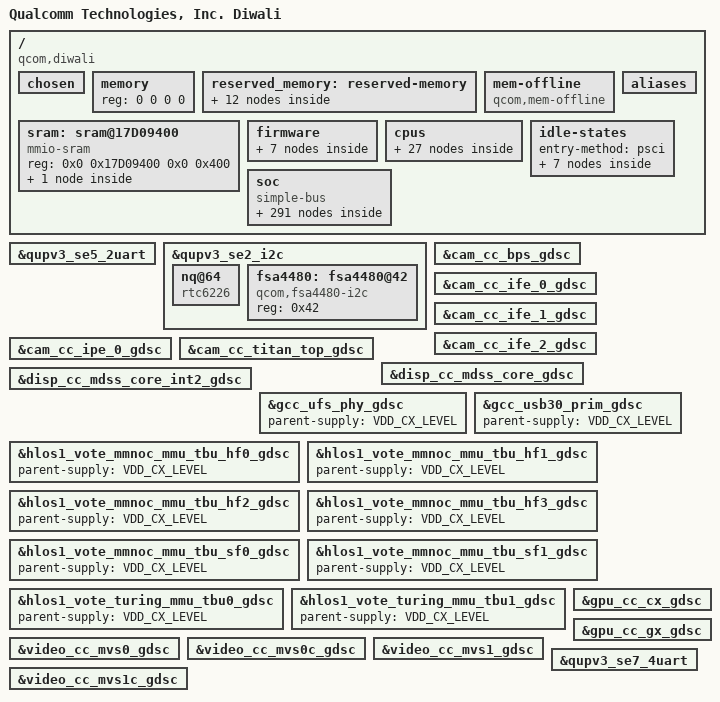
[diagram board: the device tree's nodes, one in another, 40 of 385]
#include <dt-bindings/clock/qcom,aop-qmp.h>
#include <dt-bindings/clock/qcom,camcc-diwali.h>
#include <dt-bindings/clock/qcom,dispcc-diwali.h>
#include <dt-bindings/clock/qcom,gcc-diwali.h>
#include <dt-bindings/clock/qcom,gpucc-diwali.h>
#include <dt-bindings/clock/qcom,rpmh.h>
#include <dt-bindings/clock/qcom,videocc-diwali.h>
#include <dt-bindings/interconnect/qcom,diwali.h>
#include <dt-bindings/interconnect/qcom,icc.h>
#include <dt-bindings/interrupt-controller/arm-gic.h>
#include <dt-bindings/soc/qcom,ipcc.h>
#include <dt-bindings/soc/qcom,rpmh-rsc.h>
#include <dt-bindings/regulator/qcom,rpmh-regulator-levels.h>
#include <dt-bindings/gpio/gpio.h>
#include <dt-bindings/spmi/spmi.h>

/ {
	model = "Qualcomm Technologies, Inc. Diwali";
	compatible = "qcom,diwali";
	qcom,msm-id = <506 0x10000>;
	interrupt-parent = <&intc>;

	#address-cells = <2>;
	#size-cells = <2>;

	chosen: chosen {
		stdout-path = "/soc/qcom,qup_uart@994000:115200n8";

		bootargs = "console=ttyMSM0,115200n8 loglevel=6 log_buf_len=256K kernel.panic_on_rcu_stall=1 loop.max_part=7 pcie_ports=compat msm_rtb.filter=0x237 allow_mismatched_32bit_el0 kasan=off rcupdate.rcu_expedited=1 rcu_nocbs=0-7 ftrace_dump_on_oops pstore.compress=none kpti=0 swiotlb=noforce cgroup.memory=nokmem,nosocket cpufreq.default_governor=performance page_poison=on kswapd_per_node=2";
	};

	memory { device_type = "memory"; reg = <0 0 0 0>; };

	reserved_memory: reserved-memory { };

	mem-offline {
		compatible = "qcom,mem-offline";
		offline-sizes = <0x1 0x40000000 0x0 0x40000000>,
				<0x1 0xc0000000 0x0 0x80000000>,
				<0x2 0xc0000000 0x1 0x40000000>;
		granule = <512>;
		mboxes = <&qmp_aop 0>;
	};

	aliases: aliases {
		serial0 = &qupv3_se5_2uart;
		hsuart0 = &qupv3_se7_4uart;
		ufshc1 = &ufshc_mem; /* Embedded UFS Slot */
		sdhc2 = &sdhc_2; /* SDC2 SD card slot */
	 };

	sram: sram@17D09400 {
		#address-cells = <2>;
		#size-cells = <2>;
		compatible = "mmio-sram";
		reg = <0x0 0x17D09400 0x0 0x400>;
		ranges = <0x0 0x0 0x0 0x17D09400 0x0 0x400>;

		cpu_scp_lpri: scp-shmem@0 {
			compatible = "arm,scp-shmem";
			reg = <0x0 0x0 0x0 0x400>;
		};
	};

	firmware: firmware { };

	cpus {
		#address-cells = <2>;
		#size-cells = <0>;

		CPU0: cpu@0 {
			device_type = "cpu";
			compatible = "qcom,kryo";
			reg = <0x0 0x0>;
			enable-method = "psci";
			capacity-dmips-mhz = <1024>;
			dynamic-power-coefficient = <100>;
			next-level-cache = <&L2_0>;
			cpu-idle-states = <&LITTLE_CPU_OFF &LITTLE_CPU_RAIL_OFF>;
			power-domains = <&CPU_PD0>;
			power-domain-names = "psci";
			qcom,freq-domain = <&cpufreq_hw 0 4>;
			#cooling-cells = <2>;
			L2_0: l2-cache {
			      compatible = "arm,arch-cache";
			      cache-level = <2>;
			      next-level-cache = <&L3_0>;

				L3_0: l3-cache {
					compatible = "arm,arch-cache";
					cache-level = <3>;
				};
			};
		};

		CPU1: cpu@100 {
			device_type = "cpu";
			compatible = "qcom,kryo";
			reg = <0x0 0x100>;
			enable-method = "psci";
			capacity-dmips-mhz = <1024>;
			dynamic-power-coefficient = <100>;
			next-level-cache = <&L2_0>; /* silver L2 sharing */
			cpu-idle-states = <&LITTLE_CPU_OFF &LITTLE_CPU_RAIL_OFF>;
			power-domains = <&CPU_PD1>;
			power-domain-names = "psci";
			qcom,freq-domain = <&cpufreq_hw 0 4>;
			#cooling-cells = <2>;
		};

		CPU2: cpu@200 {
			device_type = "cpu";
			compatible = "qcom,kryo";
			reg = <0x0 0x200>;
			enable-method = "psci";
			capacity-dmips-mhz = <1024>;
			dynamic-power-coefficient = <100>;
			next-level-cache = <&L2_2>;
			cpu-idle-states = <&LITTLE_CPU_OFF &LITTLE_CPU_RAIL_OFF>;
			power-domains = <&CPU_PD2>;
			power-domain-names = "psci";
			qcom,freq-domain = <&cpufreq_hw 0 4>;
			#cooling-cells = <2>;
			L2_2: l2-cache {
			      compatible = "arm,arch-cache";
			      cache-level = <2>;
			      next-level-cache = <&L3_0>;
			};
		};

		CPU3: cpu@300 {
			device_type = "cpu";
			compatible = "qcom,kryo";
			reg = <0x0 0x300>;
			enable-method = "psci";
			capacity-dmips-mhz = <1024>;
			dynamic-power-coefficient = <100>;
			next-level-cache = <&L2_2>; /* silver L2 sharing */
			cpu-idle-states = <&LITTLE_CPU_OFF &LITTLE_CPU_RAIL_OFF>;
			power-domains = <&CPU_PD3>;
			power-domain-names = "psci";
			qcom,freq-domain = <&cpufreq_hw 0 4>;
			#cooling-cells = <2>;
		};

		CPU4: cpu@400 {
			device_type = "cpu";
			compatible = "qcom,kryo";
			reg = <0x0 0x400>;
			enable-method = "psci";
			capacity-dmips-mhz = <1843>;
			dynamic-power-coefficient = <264>;
			next-level-cache = <&L2_4>;
			cpu-idle-states = <&BIG_CPU_OFF &BIG_CPU_RAIL_OFF>;
			power-domains = <&CPU_PD4>;
			power-domain-names = "psci";
			qcom,freq-domain = <&cpufreq_hw 1 4>;
			#cooling-cells = <2>;
			L2_4: l2-cache {
			      compatible = "arm,arch-cache";
			      cache-level = <2>;
			      next-level-cache = <&L3_0>;
			};
		};

		CPU5: cpu@500 {
			device_type = "cpu";
			compatible = "qcom,kryo";
			reg = <0x0 0x500>;
			enable-method = "psci";
			capacity-dmips-mhz = <1843>;
			dynamic-power-coefficient = <264>;
			next-level-cache = <&L2_5>;
			cpu-idle-states = <&BIG_CPU_OFF &BIG_CPU_RAIL_OFF>;
			power-domains = <&CPU_PD5>;
			power-domain-names = "psci";
			qcom,freq-domain = <&cpufreq_hw 1 4>;
			#cooling-cells = <2>;
			L2_5: l2-cache {
			      compatible = "arm,arch-cache";
			      cache-level = <2>;
			      next-level-cache = <&L3_0>;
			};
		};

		CPU6: cpu@600 {
			device_type = "cpu";
			compatible = "qcom,kryo";
			reg = <0x0 0x600>;
			enable-method = "psci";
			capacity-dmips-mhz = <1843>;
			dynamic-power-coefficient = <264>;
			next-level-cache = <&L2_6>;
			cpu-idle-states = <&BIG_CPU_OFF &BIG_CPU_RAIL_OFF>;
			power-domains = <&CPU_PD6>;
			power-domain-names = "psci";
			qcom,freq-domain = <&cpufreq_hw 1 4>;
			#cooling-cells = <2>;
			L2_6: l2-cache {
			      compatible = "arm,arch-cache";
			      cache-level = <2>;
			      next-level-cache = <&L3_0>;
			};
		};

		CPU7: cpu@700 {
			device_type = "cpu";
			compatible = "qcom,kryo";
			reg = <0x0 0x700>;
			enable-method = "psci";
			capacity-dmips-mhz = <1843>;
			dynamic-power-coefficient = <298>;
			next-level-cache = <&L2_7>;
			cpu-idle-states = <&BIG_CPU_OFF &BIG_CPU_RAIL_OFF>;
			power-domains = <&CPU_PD7>;
			power-domain-names = "psci";
			qcom,freq-domain = <&cpufreq_hw 2 4>;
			#cooling-cells = <2>;
			L2_7: l2-cache {
			      compatible = "arm,arch-cache";
			      cache-level = <2>;
			      next-level-cache = <&L3_0>;
			};
		};

		cpu-map {
			cluster0 {
				core0 {
					cpu = <&CPU0>;
				};

				core1 {
					cpu = <&CPU1>;
				};

				core2 {
					cpu = <&CPU2>;
				};

				core3 {
					cpu = <&CPU3>;
				};
			};

			cluster1 {
				core0 {
					cpu = <&CPU4>;
				};

				core1 {
					cpu = <&CPU5>;
				};

				core2 {
					cpu = <&CPU6>;
				};
			};

			cluster2 {
				core0 {
					cpu = <&CPU7>;
				};
			};
		};
	};

	idle-states {
		entry-method = "psci";

		LITTLE_CPU_OFF: silver-c3 {  /* C3 */
			compatible = "arm,idle-state";
			idle-state-name = "pc";
			entry-latency-us = <350>;
			exit-latency-us = <900>;
			min-residency-us = <1774>;
			arm,psci-suspend-param = <0x40000003>;
			local-timer-stop;
		};

		LITTLE_CPU_RAIL_OFF: silver-c4 {  /* C4 */
			compatible = "arm,idle-state";
			idle-state-name = "rail-pc";
			entry-latency-us = <800>;
			exit-latency-us = <750>;
			min-residency-us = <4090>;
			arm,psci-suspend-param = <0x40000004>;
			local-timer-stop;
		};

		BIG_CPU_OFF: gold-c3 {  /* C3 */
			compatible = "arm,idle-state";
			idle-state-name = "pc";
			entry-latency-us = <400>;
			exit-latency-us = <1550>;
			min-residency-us = <2207>;
			arm,psci-suspend-param = <0x40000003>;
			local-timer-stop;
		};

		BIG_CPU_RAIL_OFF: gold-c4 {  /* C4 */
			compatible = "arm,idle-state";
			idle-state-name = "rail-pc";
			entry-latency-us = <600>;
			exit-latency-us = <1550>;
			min-residency-us = <4791>;
			arm,psci-suspend-param = <0x40000004>;
			local-timer-stop;
		};

		CLUSTER_OFF: cluster-d4 { /* D4 */
			compatible = "domain-idle-state";
			idle-state-name = "l3-off";
			entry-latency-us = <1050>;
			exit-latency-us = <2500>;
			min-residency-us = <5309>;
			arm,psci-suspend-param = <0x41000044>;
		};

		CX_RET: cx-ret { /* Cx Ret */
			compatible = "domain-idle-state";
			idle-state-name = "cx-ret";
			entry-latency-us = <1561>;
			exit-latency-us = <2801>;
			min-residency-us = <8550>;
			arm,psci-suspend-param = <0x41001344>;
		};

		APSS_OFF: cluster-e3 { /* E3 */
			compatible = "domain-idle-state";
			idle-state-name = "llcc-off";
			entry-latency-us = <2700>;
			exit-latency-us = <3500>;
			min-residency-us = <13959>;
			arm,psci-suspend-param = <0x4100B344>;
		};
	};

	soc: soc { };
};

&firmware {
	qcom_scm {
		compatible = "qcom,scm";
		qcom,dload-mode = <&tcsr 0x13000>;
	};

	qtee_shmbridge {
		compatible = "qcom,tee-shared-memory-bridge";
	};

	qcom_smcinvoke {
		compatible = "qcom,smcinvoke";
	};

	android {
		compatible = "android,firmware";
		vbmeta {
			compatible = "android,vbmeta";
			parts = "vbmeta,boot,system,vendor,dtbo,recovery";
		};

		fstab {
			compatible = "android,fstab";
			vendor {
				compatible = "android,vendor";
				dev = "/dev/block/platform/soc/1d84000.ufshc/by-name/vendor";
				type = "ext4";
				mnt_flags = "ro,barrier=1,discard";
				fsmgr_flags = "wait,slotselect,avb";
				status = "ok";
			};
		};
	};
};

#include "diwali-reserved-memory.dtsi"

&reserved_memory {
	#address-cells = <2>;
	#size-cells = <2>;
	ranges;

	/* global autoconfigured region for contiguous allocations */
	system_cma: linux,cma {
		compatible = "shared-dma-pool";
		alloc-ranges = <0x0 0x00000000 0x0 0xffffffff>;
		reusable;
		alignment = <0x0 0x400000>;
		size = <0x0 0x2000000>;
		linux,cma-default;
	};

	ramoops_mem: ramoops_region {
		compatible = "ramoops";
		alloc-ranges = <0x0 0x00000000 0xffffffff 0xffffffff>;
		size = <0x0 0x200000>;
		pmsg-size = <0x200000>;
		mem-type = <2>;
	};

	non_secure_display_memory: non_secure_display_region {
		compatible = "shared-dma-pool";
		reusable;
		alloc-ranges = <0x0 0x00000000 0x0 0xffffffff>;
		size = <0x0 0xa400000>;
		alignment = <0x0 0x400000>;
	};

	demura_heap_memory: demura_heap_region {
		compatible = "shared-dma-pool";
		reusable;
		alloc-ranges = <0x1 0x00000000 0xfffffffe 0xffffffff>;
		size = <0x0 0x2800000>;
		alignment = <0x0 0x400000>;
	};

	va_md_mem: va_md_mem_region {
		compatible = "shared-dma-pool";
		alloc-ranges = <0x1 0x00000000 0xfffffffe 0xffffffff>;
		reusable;
		size = <0 0x1000000>;
	};

	cdsp_cvp_mem: cdsp_cvp_region {
		compatible = "shared-dma-pool";
		alloc-ranges = <0x0 0x00000000 0x0 0xffffffff>;
		reusable;
		alignment = <0x0 0x400000>;
		size = <0x0 0x400000>;
	};

	audio_cma_mem: audio_cma_region {
		compatible = "shared-dma-pool";
		alloc-ranges = <0x0 0x00000000 0x0 0xffffffff>;
		reusable;
		alignment = <0x0 0x400000>;
		size = <0x0 0x1C00000>;
	};

	adsp_mem_heap: adsp_heap_region {
		compatible = "shared-dma-pool";
		alloc-ranges = <0x0 0x00000000 0x0 0xffffffff>;
		reusable;
		alignment = <0x0 0x400000>;
		size = <0x0 0xC00000>;
	};

	sdsp_mem: sdsp_region {
		compatible = "shared-dma-pool";
		alloc-ranges = <0x0 0x00000000 0x0 0xffffffff>;
		reusable;
		alignment = <0x0 0x400000>;
		size = <0x0 0x400000>;
	};

	user_contig_mem: user_contig_region {
		compatible = "shared-dma-pool";
		alloc-ranges = <0x0 0x00000000 0x0 0xffffffff>;
		reusable;
		alignment = <0x0 0x400000>;
		size = <0x0 0x1000000>;
	};

	qseecom_mem: qseecom_region {
		compatible = "shared-dma-pool";
		alloc-ranges = <0x0 0x00000000 0x0 0xffffffff>;
		reusable;
		alignment = <0x0 0x400000>;
		size = <0x0 0x1400000>;
	};

	qseecom_ta_mem: qseecom_ta_region {
		compatible = "shared-dma-pool";
		alloc-ranges = <0x0 0x00000000 0x0 0xffffffff>;
		reusable;
		alignment = <0x0 0x400000>;
		size = <0x0 0x1000000>;
	};
};

&soc {
	#address-cells = <1>;
	#size-cells = <1>;
	ranges = <0 0 0 0xffffffff>;
	compatible = "simple-bus";

	psci {
		compatible = "arm,psci-1.0";
		method = "smc";

		CPU_PD0: cpu-pd0 {
			#power-domain-cells = <0>;
			power-domains = <&CLUSTER_PD>;
		};

		CPU_PD1: cpu-pd1 {
			#power-domain-cells = <0>;
			power-domains = <&CLUSTER_PD>;
		};

		CPU_PD2: cpu-pd2 {
			#power-domain-cells = <0>;
			power-domains = <&CLUSTER_PD>;
		};

		CPU_PD3: cpu-pd3 {
			#power-domain-cells = <0>;
			power-domains = <&CLUSTER_PD>;
		};

		CPU_PD4: cpu-pd4 {
			#power-domain-cells = <0>;
			power-domains = <&CLUSTER_PD>;
		};

		CPU_PD5: cpu-pd5 {
			#power-domain-cells = <0>;
			power-domains = <&CLUSTER_PD>;
		};

		CPU_PD6: cpu-pd6 {
			#power-domain-cells = <0>;
			power-domains = <&CLUSTER_PD>;
		};

		CPU_PD7: cpu-pd7 {
			#power-domain-cells = <0>;
			power-domains = <&CLUSTER_PD>;
		};

		CLUSTER_PD: cluster-pd {
			#power-domain-cells = <0>;
			domain-idle-states = <&CLUSTER_OFF &CX_RET &APSS_OFF>;
		};
	};

	slimbam: bamdma@3304000 {
		compatible = "qcom,bam-v1.7.0";
		qcom,controlled-remotely;
		reg = <0x3304000 0x20000>, <0x326b000 0x1000>;
		reg-names = "bam", "bam_remote_mem";
		num-channels  = <31>;
		interrupts = <0 164 IRQ_TYPE_LEVEL_HIGH>;
		#dma-cells = <1>;
		qcom,ee = <1>;
		qcom,num-ees = <2>;
	};

	slim_msm: slim@3340000 {
		compatible = "qcom,slim-ngd-v1.5.0";
		reg = <0x3340000 0x2C000>, <0x326a000 0x1000>;
		reg-names = "ctrl", "slimbus_remote_mem";
		interrupts = <0 163 IRQ_TYPE_LEVEL_HIGH>;
		qcom,apps-ch-pipes = <0x0>;
		qcom,ea-pc = <0x400>;
		dmas = <&slimbam 3>, <&slimbam 4>;
		dma-names = "rx", "tx";
		#address-cells = <1>;
		#size-cells = <0>;
		status = "ok";
		ngd@1 {
			reg = <1>;
			#address-cells = <1>;
			#size-cells = <1>;

			/* slimbus child nodes */
			slimbus: btfmslim-driver {
				compatible = "slim217,221";
				reg = <1 0>;
			};
		};
	};

	bluetooth: bt_wcn6x5x {
		compatible = "qcom,wcn6750-bt";
		pinctrl-names = "default";
		pinctrl-0 = <&bt_en_sleep>;
		qcom,bt-reset-gpio = <&tlmm 114 0>; /* BT_EN */
		qcom,bt-sw-ctrl-gpio = <&tlmm 83 0>; /* SW_CTRL */
		qcom,wl-reset-gpio = <&tlmm 49 0>; /* WL_EN */

		qcom,bt-vdd-io-supply = <&L18B>;  /* IO */
		qcom,bt-vdd-aon-supply = <&S7B>;
		qcom,bt-vdd-dig-supply = <&S7B>; /* BT_CX_MX */
		qcom,bt-vdd-rfacmn-supply = <&S7B>;
		qcom,bt-vdd-rfa-0p8-supply = <&S7B>;
		qcom,bt-vdd-rfa1-supply = <&S1B>; /*RFA 1p7*/
		qcom,bt-vdd-rfa2-supply = <&S8B>; /*RFA 1p2*/
		qcom,bt-vdd-ipa-2p2-supply = <&S1C>; /*IPA 2p2*/
		qcom,bt-vdd-asd-supply = <&L11C>;

		/* max voltage are set to regulator max voltage supported */
		qcom,bt-vdd-io-config = <1800000 2000000 0 1>;
		qcom,bt-vdd-aon-config = <824000 1120000 0 1>;
		qcom,bt-vdd-dig-config = <824000 1120000 0 1>;
		qcom,bt-vdd-rfacmn-config  = <824000 1120000 0 1>;
		qcom,bt-vdd-rfa-0p8-config  = <824000 1120000 0 1>;
		qcom,bt-vdd-rfa1-config = <1872000 2040000 0 1>;
		qcom,bt-vdd-rfa2-config = <1256000 1500000 0 1>;
		qcom,bt-vdd-ipa-2p2-config = <2200000 2210000 0 1>;
		qcom,bt-vdd-asd-config = <2800000 3544000 0 1>;
	};

	intc: interrupt-controller@17100000 {
		compatible = "arm,gic-v3";
		#interrupt-cells = <3>;
		interrupt-controller;
		ranges;
		#redistributor-regions = <1>;
		redistributor-stride = <0x0 0x40000>;
		reg = <0x17100000 0x10000>,     /* GICD */
		      <0x17180000 0x200000>;    /* GICR * 8 */
		interrupts = <GIC_PPI 9 IRQ_TYPE_LEVEL_LOW>;

		gic_its: msi-controller@17140000 {
			compatible = "arm,gic-v3-its";
			msi-controller;
			#msi-cells = <1>;
			reg = <0x17140000 0x20000>;
		};
	};

	tlmm: pinctrl@f000000 {
		compatible = "qcom,diwali-pinctrl";
		reg = <0x0F000000 0x1000000>;
		interrupts = <GIC_SPI 208 IRQ_TYPE_LEVEL_HIGH>;
		gpio-controller;
		#gpio-cells = <2>;
		interrupt-controller;
		#interrupt-cells = <2>;
		wakeup-parent = <&pdc>;
		qcom,gpios-reserved = <32 33 34 35>;
	};

	tlmm-vm-mem-access {
		compatible = "qcom,tlmm-vm-mem-access";
		qcom,master;
		tlmm-vm-gpio-list = <>;
	};

	wdog: qcom,wdt@17410000 {
		compatible = "qcom,msm-watchdog";
		reg = <0x17410000 0x1000>;
		reg-names = "wdt-base";
		interrupts = <GIC_SPI 0 IRQ_TYPE_LEVEL_HIGH>;
	};

	arch_timer: timer {
		compatible = "arm,armv8-timer";
		interrupts = <GIC_PPI 13 (GIC_CPU_MASK_SIMPLE(8) | IRQ_TYPE_LEVEL_LOW)>,
			     <GIC_PPI 14 (GIC_CPU_MASK_SIMPLE(8) | IRQ_TYPE_LEVEL_LOW)>,
			     <GIC_PPI 11 (GIC_CPU_MASK_SIMPLE(8) | IRQ_TYPE_LEVEL_LOW)>,
			     <GIC_PPI 12 (GIC_CPU_MASK_SIMPLE(8) | IRQ_TYPE_LEVEL_LOW)>;
		clock-frequency = <19200000>;
	};

	apps_rsc: rsc@17a00000 {
		label = "apps_rsc";
		compatible = "qcom,rpmh-rsc";
		reg = <0x17a00000 0x10000>,
		      <0x17a10000 0x10000>,
		      <0x17a20000 0x10000>;
		reg-names = "drv-0", "drv-1", "drv-2";
		interrupts = <GIC_SPI 3 IRQ_TYPE_LEVEL_HIGH>,
			     <GIC_SPI 4 IRQ_TYPE_LEVEL_HIGH>,
			     <GIC_SPI 5 IRQ_TYPE_LEVEL_HIGH>;
		qcom,tcs-offset = <0xd00>;
		qcom,drv-id = <2>;
		qcom,tcs-config = <ACTIVE_TCS		3>,
				  <SLEEP_TCS		2>,
				  <WAKE_TCS		2>,
				  <CONTROL_TCS		0>,
				  <FAST_PATH_TCS	1>;
		power-domains = <&CLUSTER_PD>;

		rpmhcc: qcom,rpmhclk {
			compatible = "qcom,diwali-rpmh-clk";
			#clock-cells = <1>;
		};

		apps_bcm_voter: bcm_voter {
			compatible = "qcom,bcm-voter";
		};

		dcvs_fp: qcom,dcvs-fp {
			compatible = "qcom,dcvs-fp";
			qcom,ddr-bcm-name = "MC3";
			qcom,llcc-bcm-name = "SH5";
		};
	};

	cluster-device {
		compatible = "qcom,lpm-cluster-dev";
		power-domains = <&CLUSTER_PD>;
	};

	disp_rsc: rsc@af20000 {
		lable = "disp_rsc";
		compatible = "qcom,rpmh-rsc";
		reg = <0xaf20000 0x10000>;
		reg-names = "drv-0";
		interrupts = <GIC_SPI 129 IRQ_TYPE_LEVEL_HIGH>;
		clocks = <&dispcc DISP_CC_MDSS_RSCC_AHB_CLK>;
		qcom,tcs-offset = <0x1c00>;
		qcom,drv-id = <0>;
		qcom,tcs-config = <ACTIVE_TCS		0>,
				  <SLEEP_TCS		1>,
				  <WAKE_TCS		1>,
				  <CONTROL_TCS		0>,
				  <FAST_PATH_TCS	0>;

		disp_bcm_voter: bcm_voter {
			compatible = "qcom,bcm-voter";
			qcom,tcs-wait = <QCOM_ICC_TAG_AMC>;
		};
	};

	pdc: interrupt-controller@b220000 {
		compatible = "qcom,diwali-pdc", "qcom,pdc";
		reg = <0xb220000 0x30000>, <0x174000f0 0x64>;
		reg-names = "pdc-interrupt-base", "apps-shared-spi-cfg";
		qcom,pdc-ranges = <0 480 94>, <94 609 31>, <125 63 1>,
				  <126 716 12>;
		#interrupt-cells = <2>;
		interrupt-parent = <&intc>;
		interrupt-controller;
	};

	cpuss-sleep-stats@17800054 {
		compatible = "qcom,cpuss-sleep-stats";
		reg = <0x17800054 0x4>, <0x17810054 0x4>, <0x17820054 0x4>,
		    <0x17830054 0x4>, <0x17840054 0x4>, <0x17850054 0x4>,
		    <0x17860054 0x4>, <0x17870054 0x4>, <0x178A0098 0x4>,
		    <0x178C0000 0x10000>;
		reg-names = "seq_lpm_cntr_cfg_cpu0", "seq_lpm_cntr_cfg_cpu1",
			  "seq_lpm_cntr_cfg_cpu2", "seq_lpm_cntr_cfg_cpu3",
			  "seq_lpm_cntr_cfg_cpu4", "seq_lpm_cntr_cfg_cpu5",
			  "seq_lpm_cntr_cfg_cpu6", "seq_lpm_cntr_cfg_cpu7",
			  "l3_seq_lpm_cntr_cfg", "apss_seq_mem_base";
		num-cpus = <8>;
	};

	rpmh-sleep-stats@c3f0000 {
		compatible = "qcom,rpmh-sleep-stats";
		reg = <0xc3f0000 0x400>;
		ss-name = "modem", "adsp", "adsp_island",
			  "cdsp", "apss", "wpss";
	};

	sys-pm-vx@c320000 {
		compatible = "qcom,sys-pm-violators", "qcom,sys-pm-diwali";
		reg = <0xc320000 0x0400>;
		mboxes = <&qmp_aop 0>;
		mbox-names = "aop";
	};

	subsystem-sleep-stats {
		compatible = "qcom,subsystem-sleep-stats";
		reg = <0xc3f0000 0x400>;
	};

	memtimer: timer@17420000 {
		#address-cells = <1>;
		#size-cells = <1>;
		ranges;
		compatible = "arm,armv7-timer-mem";
		reg = <0x17420000 0x1000>;
		clock-frequency = <19200000>;

		frame@17421000 {
			frame-number = <0>;
			interrupts = <GIC_SPI 8 IRQ_TYPE_LEVEL_HIGH>,
				     <GIC_SPI 6 IRQ_TYPE_LEVEL_HIGH>;
			reg = <0x17421000 0x1000>,
			      <0x17422000 0x1000>;
		};

		frame@17423000 {
			frame-number = <1>;
			interrupts = <GIC_SPI 9 IRQ_TYPE_LEVEL_HIGH>;
			reg = <0x17423000 0x1000>;
			status = "disabled";
		};

		frame@17425000 {
			frame-number = <2>;
			interrupts = <GIC_SPI 10 IRQ_TYPE_LEVEL_HIGH>;
			reg = <0x17425000 0x1000>;
			status = "disabled";
		};

		frame@17427000 {
			frame-number = <3>;
			interrupts = <GIC_SPI 11 IRQ_TYPE_LEVEL_HIGH>;
			reg = <0x17427000 0x1000>;
			status = "disabled";
		};

		frame@17429000 {
			frame-number = <4>;
			interrupts = <GIC_SPI 12 IRQ_TYPE_LEVEL_HIGH>;
			reg = <0x17429000 0x1000>;
			status = "disabled";
		};

		frame@1742b000 {
			frame-number = <5>;
			interrupts = <GIC_SPI 13 IRQ_TYPE_LEVEL_HIGH>;
			reg = <0x1742b000 0x1000>;
			status = "disabled";
		};

		frame@1742d000 {
			frame-number = <6>;
			interrupts = <GIC_SPI 14 IRQ_TYPE_LEVEL_HIGH>;
			reg = <0x1742d000 0x1000>;
			status = "disabled";
		};
	};

	rimps: qcom,rimps@17400000 {
		#address-cells = <2>;
		#size-cells = <2>;
		compatible = "qcom,rimps";
		reg =   <0x17400000 0x10>,
			<0x17d90000 0x2000>;
		#mbox-cells = <1>;
		interrupts = <GIC_SPI 62 IRQ_TYPE_LEVEL_HIGH>;
	};

	scmi: qcom,scmi {
		#address-cells = <1>;
		#size-cells = <0>;
		compatible = "arm,scmi";
		mboxes = <&rimps 0>;
		mbox-names = "tx";
		shmem = <&cpu_scp_lpri>;

		scmi_plh: protocol@81 {
			reg = <0x81>;
			#clock-cells = <1>;
		};
	};

	rimps_log: qcom,rimps_log@17d09c00 {
		compatible = "qcom,rimps-log";
		reg = <0x17d09c00 0x200>, <0x17d09e00 0x200>;
		mboxes = <&rimps 1>;
	};

	ipcc_mproc: qcom,ipcc@ed18000 {
		compatible = "qcom,ipcc";
		reg = <0xed18000 0x1000>;
		interrupts = <GIC_SPI 229 IRQ_TYPE_LEVEL_HIGH>;
		interrupt-controller;
		#interrupt-cells = <3>;
		#mbox-cells = <2>;
	};

	tcsr: syscon@1fc0000 {
		compatible = "syscon";
		reg = <0x1fc0000 0x30000>;
	};

	clocks {
		xo_board: xo_board {
			compatible = "fixed-clock";
			clock-frequency = <76800000>;
			clock-output-names = "xo_board";
			#clock-cells = <0>;
		};

		sleep_clk: sleep_clk {
			compatible = "fixed-clock";
			clock-frequency = <32000>;
			clock-output-names = "sleep_clk";
			#clock-cells = <0>;
		};

		pcie_0_pipe_clk: pcie_0_pipe_clk {
			compatible = "fixed-clock";
			clock-frequency = <1000>;
			clock-output-names = "pcie_0_pipe_clk";
			#clock-cells = <0>;
		};

		ufs_phy_rx_symbol_0_clk: ufs_phy_rx_symbol_0_clk {
			compatible = "fixed-clock";
			clock-frequency = <1000>;
			clock-output-names = "ufs_phy_rx_symbol_0_clk";
			#clock-cells = <0>;
		};

		ufs_phy_rx_symbol_1_clk: ufs_phy_rx_symbol_1_clk {
			compatible = "fixed-clock";
			clock-frequency = <1000>;
			clock-output-names = "ufs_phy_rx_symbol_1_clk";
			#clock-cells = <0>;
		};

		ufs_phy_tx_symbol_0_clk: ufs_phy_tx_symbol_0_clk {
			compatible = "fixed-clock";
			clock-frequency = <1000>;
			clock-output-names = "ufs_phy_tx_symbol_0_clk";
			#clock-cells = <0>;
		};

		usb3_phy_wrapper_gcc_usb30_pipe_clk: usb3_phy_wrapper_gcc_usb30_pipe_clk {
			compatible = "fixed-clock";
			clock-frequency = <1000>;
			clock-output-names = "usb3_phy_wrapper_gcc_usb30_pipe_clk";
			#clock-cells = <0>;
		};
	};

	camcc: clock-controller@ad00000 {
		compatible = "qcom,diwali-camcc", "syscon";
		reg = <0xad00000 0x20000>;
		reg-name = "cc_base";
		vdd_cam_cx-supply = <&VDD_CAM_CX_LEVEL>;
		vdd_mxa-supply = <&VDD_MXA_LEVEL>;
		vdd_mxc-supply = <&VDD_MXC_LEVEL>;
		clocks = <&rpmhcc RPMH_CXO_CLK>,
			<&rpmhcc RPMH_CXO_CLK_A>,
			<&sleep_clk>,
			<&gcc GCC_CAMERA_AHB_CLK>;
		clock-names = "bi_tcxo", "bi_tcxo_ao", "sleep_clk", "iface";
		#clock-cells = <1>;
		#reset-cells = <1>;
	};

	dispcc: clock-controller@af00000 {
		compatible = "qcom,diwali-dispcc", "syscon";
		reg = <0xaf00000 0x20000>;
		reg-name = "cc_base";
		vdd_cx-supply = <&VDD_CX_LEVEL>;
		clocks = <&rpmhcc RPMH_CXO_CLK>,
			<&rpmhcc RPMH_CXO_CLK_A>,
			<&sleep_clk>,
			<&gcc GCC_DISP_AHB_CLK>;
		clock-names = "bi_tcxo", "bi_tcxo_ao", "sleep_clk", "iface";
		#clock-cells = <1>;
		#reset-cells = <1>;
	};

	gcc: clock-controller@100000 {
		compatible = "qcom,diwali-gcc", "syscon";
		reg = <0x100000 0x1f4200>;
		reg-name = "cc_base";
		vdd_cx-supply = <&VDD_CX_LEVEL>;
		vdd_mxa-supply = <&VDD_MXA_LEVEL>;
		clocks = <&rpmhcc RPMH_CXO_CLK>, <&sleep_clk>,
			<&ufs_phy_rx_symbol_0_clk>, <&ufs_phy_rx_symbol_1_clk>,
			<&ufs_phy_tx_symbol_0_clk>, <&usb3_phy_wrapper_gcc_usb30_pipe_clk>;
		clock-names = "bi_tcxo", "sleep_clk",
			"ufs_phy_rx_symbol_0_clk", "ufs_phy_rx_symbol_1_clk",
			"ufs_phy_tx_symbol_0_clk", "usb3_phy_wrapper_gcc_usb30_pipe_clk";

		protected-clocks = <GCC_DDRSS_PCIE_SF_TBU_CLK>, <GCC_PCIE_0_AUX_CLK>,
		<GCC_PCIE_0_AUX_CLK_SRC>, <GCC_PCIE_0_CFG_AHB_CLK>,
		<GCC_PCIE_0_CLKREF_EN>, <GCC_PCIE_0_MSTR_AXI_CLK>,
		<GCC_PCIE_0_PHY_RCHNG_CLK>, <GCC_PCIE_0_PHY_RCHNG_CLK_SRC>,
		<GCC_PCIE_0_PIPE_CLK>, <GCC_PCIE_0_PIPE_CLK_SRC>,
		<GCC_PCIE_0_SLV_AXI_CLK>, <GCC_PCIE_0_SLV_Q2A_AXI_CLK>,
		<GCC_QMIP_PCIE_AHB_CLK>;

		#clock-cells = <1>;
		#reset-cells = <1>;
	};

	gpucc: clock-controller@3d90000 {
		compatible = "qcom,diwali-gpucc", "syscon";
		reg = <0x3d90000 0xA000>;
		reg-names = "cc_base";
		vdd_cx-supply = <&VDD_CX_LEVEL>;
		vdd_mxa-supply = <&VDD_MXA_LEVEL>;
		clocks = <&rpmhcc RPMH_CXO_CLK>,
			<&gcc GCC_GPU_GPLL0_CLK_SRC>,
			<&gcc GCC_GPU_GPLL0_DIV_CLK_SRC>;
		clock-names = "bi_tcxo", "gpll0_out_main", "gpll0_out_main_div";
		#clock-cells = <1>;
		#reset-cells = <1>;
	};

	videocc: clock-controller@aaf0000 {
		compatible = "qcom,diwali-videocc", "syscon";
		reg = <0xaaf0000 0x10000>;
		reg-name = "cc_base";
		vdd_cx-supply = <&VDD_CX_LEVEL>;
		vdd_mxc-supply = <&VDD_MXC_LEVEL>;
		clocks = <&rpmhcc RPMH_CXO_CLK>,
			<&rpmhcc RPMH_CXO_CLK_A>,
			<&sleep_clk>,
			<&gcc GCC_VIDEO_AHB_CLK>;
		clock-names = "bi_tcxo", "bi_tcxo_ao", "sleep_clk", "iface";
		#clock-cells = <1>;
		#reset-cells = <1>;
	};

	llcc_pmu: llcc-pmu@19095000 {
		compatible = "qcom,llcc-pmu-ver2";
		reg = <0x19095000 0x300>;
		reg-names = "lagg-base";
	};

	qcom_pmu: qcom,pmu {
		compatible = "qcom,pmu";
		qcom,long-counter;
		qcom,pmu-events-tbl =
			< 0x0008 0xFF 0x02 0xFF >,
			< 0x0011 0xFF 0x01 0xFF >,
			< 0x0017 0xFF 0xFF 0xFF >,
			< 0x0018 0xFF 0xFF 0xFF >,
			< 0x0037 0xFF 0xFF 0xFF >,
			< 0x002B 0xFF 0xFF 0xFF >,
			< 0x1000 0xFF 0xFF 0xFF >;
	};

	ddr_freq_table: ddr-freq-table {
		ddr4 {
			qcom,ddr-type = <7>;
			qcom,freq-tbl =
				<  547000 >,
				<  768000 >,
				< 1017000 >,
				< 1353600 >,
				< 1555000 >,
				< 1708000 >,
				< 2092000 >;
		};

		ddr5 {
			qcom,ddr-type = <8>;
			qcom,freq-tbl =
				<  547000 >,
				<  768000 >,
				< 1555000 >,
				< 1708000 >,
				< 2092000 >,
				< 2736000 >,
				< 3196000 >;
		};
	};

	llcc_freq_table: llcc-freq-table {
		qcom,freq-tbl =
			<  300000 >,
			<  466000 >,
			<  600000 >,
			<  806000 >,
			<  933000 >,
			< 1066000 >;
	};

	ddrqos_freq_table: ddrqos-freq-table {
		qcom,freq-tbl =
		< 0 >,
		< 1 >;
};

	qcom_dcvs: qcom,dcvs {
		compatible = "qcom,dcvs";
		#address-cells = <1>;
		#size-cells = <1>;
		ranges;

		qcom_l3_dcvs_hw: l3 {
			compatible = "qcom,dcvs-hw";
			qcom,dcvs-hw-type = <2>;
			qcom,bus-width = <32>;
			reg = <0x17d90000 0x4000>, <0x17d90100 0xa0>;
			reg-names = "l3-base", "l3tbl-base";

			l3_dcvs_sp: sp {
				compatible = "qcom,dcvs-path";
				qcom,dcvs-path-type = <0>;
				qcom,shared-offset = <0x0090>;
			};
		};

		qcom_ddr_dcvs_hw: ddr {
			compatible = "qcom,dcvs-hw";
			qcom,dcvs-hw-type = <0>;
			qcom,bus-width = <4>;
			qcom,freq-tbl = <&ddr_freq_table>;

			ddr_dcvs_sp: sp {
				compatible = "qcom,dcvs-path";
				qcom,dcvs-path-type = <0>;
				interconnects = <&mc_virt MASTER_LLCC
						 &mc_virt SLAVE_EBI1>;
			};

			ddr_dcvs_fp: fp {
				compatible = "qcom,dcvs-path";
				qcom,dcvs-path-type = <1>;
				qcom,fp-voter = <&dcvs_fp>;
			};

		};

		qcom_llcc_dcvs_hw: llcc {
			compatible = "qcom,dcvs-hw";
			qcom,dcvs-hw-type = <1>;
			qcom,bus-width = <16>;
			qcom,freq-tbl = <&llcc_freq_table>;

			llcc_dcvs_sp: sp {
				compatible = "qcom,dcvs-path";
				qcom,dcvs-path-type = <0>;
				interconnects = <&gem_noc MASTER_APPSS_PROC
						 &gem_noc SLAVE_LLCC>;
			};

			llcc_dcvs_fp: fp {
				compatible = "qcom,dcvs-path";
				qcom,dcvs-path-type = <1>;
				qcom,fp-voter = <&dcvs_fp>;
			};

		};

		qcom_ddrqos_dcvs_hw: ddrqos {
			compatible = "qcom,dcvs-hw";
			qcom,dcvs-hw-type = <3>;
			qcom,bus-width = <1>;
			qcom,freq-tbl = <&ddrqos_freq_table>;

			ddrqos_dcvs_sp: sp {
				compatible = "qcom,dcvs-path";
				qcom,dcvs-path-type = <0>;
				interconnects = <&mc_virt MASTER_LLCC
					 &mc_virt SLAVE_EBI1>;
			};
		};
	};

	qcom_memlat: qcom,memlat {
		compatible = "qcom,memlat";

		ddr {
			compatible = "qcom,memlat-grp";
			qcom,target-dev = <&qcom_ddr_dcvs_hw>;
			qcom,sampling-path = <&ddr_dcvs_fp>;
			qcom,miss-ev = <0x1000>;

			silver {
				compatible = "qcom,memlat-mon";
				qcom,cpulist = <&CPU0 &CPU1 &CPU2 &CPU3>;
				qcom,sampling-enabled;
				ddr4-tbl {
					qcom,ddr-type = <7>;
					qcom,cpufreq-memfreq-tbl =
						< 1094400  547000 >,
						< 1555200  768000 >,
						< 1804800 1017000 >;
				};

				ddr5-tbl {
					qcom,ddr-type = <8>;
					qcom,cpufreq-memfreq-tbl =
						< 1094400  547000 >,
						< 1555200  768000 >,
						< 1804800 1555000 >;
				};
			};

			gold {
				compatible = "qcom,memlat-mon";
				qcom,cpulist = <&CPU4 &CPU5 &CPU6>;
				qcom,sampling-enabled;
				ddr4-tbl {
					qcom,ddr-type = <7>;
					qcom,cpufreq-memfreq-tbl =
						<  940800  547000 >,
						< 1132800 1017000 >,
						< 1651200 1555000 >,
						< 2208000 1708000 >,
						< 2361600 2092000 >;
				};

				ddr5-tbl {
					qcom,ddr-type = <8>;
					qcom,cpufreq-memfreq-tbl =
						<  940800  547000 >,
						< 1132800  768000 >,
						< 1651200 1555000 >,
						< 1804800 1708000 >,
						< 2208000 2092000 >,
						< 2361600 3196000 >;
				};
			};

			prime {
				compatible = "qcom,memlat-mon";
				qcom,cpulist = <&CPU7>;
				qcom,sampling-enabled;
				ddr4-tbl {
					qcom,ddr-type = <7>;
					qcom,cpufreq-memfreq-tbl =
						<  940800  547000 >,
						< 1094400 1017000 >,
						< 1612800 1555000 >,
						< 2169600 1708000 >,
						< 2400000 2092000 >;
				};

				ddr5-tbl {
					qcom,ddr-type = <8>;
					qcom,cpufreq-memfreq-tbl =
						<  940800  547000 >,
						< 1094400  768000 >,
						< 1612800 1555000 >,
						< 1977600 1708000 >,
						< 2169600 2092000 >,
						< 2400000 3196000 >;
				};
			};

			silver-compute {
				compatible = "qcom,memlat-mon";
				qcom,cpulist = <&CPU0 &CPU1 &CPU2 &CPU3>;
				qcom,sampling-enabled;
				qcom,compute-mon;
				ddr4-tbl {
					qcom,ddr-type = <7>;
					qcom,cpufreq-memfreq-tbl =
						< 1555200  547000 >,
						< 1804800  768000 >;
				};

				ddr5-tbl {
					qcom,ddr-type = <8>;
					qcom,cpufreq-memfreq-tbl =
						< 1552000  547000 >,
						< 1804800  768000 >;
				};
			};

			gold-compute {
				compatible = "qcom,memlat-mon";
				qcom,cpulist = <&CPU4 &CPU5 &CPU6 &CPU7>;
				qcom,sampling-enabled;
				qcom,compute-mon;
				ddr4-tbl {
					qcom,ddr-type = <7>;
					qcom,cpufreq-memfreq-tbl =
						<  940800  547000 >,
						< 1132800  768000 >,
						< 1651200 1017000 >,
						< 1804800 1555000 >,
						< 2208000 1708000 >,
						< 2361600 2092000 >;
				};

				ddr5-tbl {
					qcom,ddr-type = <8>;
					qcom,cpufreq-memfreq-tbl =
						<  940800  547000 >,
						< 1132800  768000 >,
						< 1651200 1555000 >,
						< 1804800 1708000 >,
						< 2208000 2092000 >,
						< 2361600 3196000 >;
				};
			};

			prime-latfloor {
				compatible = "qcom,memlat-mon";
				qcom,cpulist = <&CPU7>;
				qcom,sampling-enabled;
				ddr4-tbl {
					qcom,ddr-type = <7>;
					qcom,cpufreq-memfreq-tbl =
						< 2284800  547000 >,
						< 2707200 2092000 >;
				};

				ddr5-tbl {
					qcom,ddr-type = <8>;
					qcom,cpufreq-memfreq-tbl =
						< 2284800  547000 >,
						< 2707200 3196000 >;
				};
			};
		};

		llcc {
			compatible = "qcom,memlat-grp";
			qcom,target-dev = <&qcom_llcc_dcvs_hw>;
			qcom,sampling-path = <&llcc_dcvs_fp>;
			qcom,miss-ev = <0x37>;

			silver {
				compatible = "qcom,memlat-mon";
				qcom,cpulist = <&CPU0 &CPU1 &CPU2 &CPU3>;
				qcom,cpufreq-memfreq-tbl =
					< 1094400  300000 >,
					< 1555200  466000 >,
					< 1804800  600000 >;
				qcom,sampling-enabled;
			};

			gold {
				compatible = "qcom,memlat-mon";
				qcom,cpulist = <&CPU4 &CPU5 &CPU6 &CPU7>;
				qcom,cpufreq-memfreq-tbl =
					<  652800  300000 >,
					<  940800  466000 >,
					< 1382400  600000 >,
					< 1651200  806000 >,
					< 2208000  933000 >,
					< 2361600 1066000 >;
				qcom,sampling-enabled;
			};

			gold-compute {
				compatible = "qcom,memlat-mon";
				qcom,cpulist = <&CPU4 &CPU5 &CPU6 &CPU7>;
				qcom,cpufreq-memfreq-tbl =
					< 1977600  300000 >,
					< 2707200  600000 >;
				qcom,sampling-enabled;
				qcom,compute-mon;
			};
		};

		l3 {
			compatible = "qcom,memlat-grp";
			qcom,target-dev = <&qcom_l3_dcvs_hw>;
			qcom,sampling-path = <&l3_dcvs_sp>;
			qcom,miss-ev = <0x17>;
			qcom,wb-ev = <0x18>;
			qcom,access-ev = <0x2B>;

			silver {
				compatible = "qcom,memlat-mon";
				qcom,cpulist = <&CPU0 &CPU1 &CPU2 &CPU3>;
				qcom,cpufreq-memfreq-tbl =
					<  403200  307200 >,
					<  614400  537600 >,
					<  806400  652800 >,
					<  902400  748800 >,
					< 1094400  844800 >,
					< 1228800 1056000 >,
					< 1363200 1209600 >,
					< 1555200 1344000 >,
					< 1651200 1612800 >,
					< 1804800 1670400 >;
				qcom,sampling-enabled;
			};

			gold {
				compatible = "qcom,memlat-mon";
				qcom,cpulist = <&CPU4 &CPU5 &CPU6>;
				qcom,cpufreq-memfreq-tbl =
					<  940800  537600 >,
					< 1132800  748800 >,
					< 1382400  979200 >,
					< 1651200 1209600 >,
					< 1804800 1344000 >,
					< 2054400 1612800 >,
					< 2208000 1670400 >;
				qcom,sampling-enabled;
			};

			prime {
				compatible = "qcom,memlat-mon";
				qcom,cpulist = <&CPU7>;
				qcom,cpufreq-memfreq-tbl =
					< 1094400  537600 >,
					< 1401600  748800 >,
					< 1766400 1209600 >,
					< 1977600 1344000 >,
					< 2169600 1612800 >,
					< 2400000 1670400 >;
				qcom,sampling-enabled;
			};

			prime-compute {

				compatible = "qcom,memlat-mon";
				qcom,cpulist = <&CPU7>;
				qcom,cpufreq-memfreq-tbl =
					< 1977600  307200 >,
					< 2707200 1344000 >;
				qcom,sampling-enabled;
				qcom,compute-mon;
			};
		};

		ddrqos {
			compatible = "qcom,memlat-grp";
			qcom,target-dev = <&qcom_ddrqos_dcvs_hw>;
			qcom,sampling-path = <&ddrqos_dcvs_sp>;
			qcom,miss-ev = <0x1000>;

			ddrqos_gold_lat: gold {
				compatible = "qcom,memlat-mon";
				qcom,cpulist = <&CPU4 &CPU5 &CPU6 &CPU7>;
				qcom,cpufreq-memfreq-tbl =
					< 2169600 0 >,
					< 2707200 1 >;
				qcom,sampling-enabled;
			};

			ddrqos_prime_latfloor: prime-latfloor {
				compatible = "qcom,memlat-mon";
				qcom,cpulist = <&CPU7>;
				qcom,cpufreq-memfreq-tbl =
					< 2169600 0 >,
					< 2707200 1 >;
				qcom,sampling-enabled;
			};
		};
	};

	bwmon_llcc: qcom,bwmon-llcc@190b6400 {
		compatible = "qcom,bwmon4";
		reg = <0x190b6400 0x300>, <0x190b6300 0x200>;
		reg-names = "base", "global_base";
		interrupts = <GIC_SPI 581 IRQ_TYPE_LEVEL_HIGH>;
		qcom,mport = <0>;
		qcom,hw-timer-hz = <19200000>;
		qcom,count-unit = <0x10000>;
		qcom,target-dev = <&qcom_llcc_dcvs_hw>;
	};

	bwmon_ddr: qcom,bwmon-ddr@19091000 {
		compatible = "qcom,bwmon5";
		reg = <0x19091000 0x1000>;
		reg-names = "base";
		interrupts = <GIC_SPI 81 IRQ_TYPE_LEVEL_HIGH>;
		qcom,hw-timer-hz = <19200000>;
		qcom,count-unit = <0x10000>;
		qcom,target-dev = <&qcom_ddr_dcvs_hw>;
	};

	cpufreq_hw: qcom,cpufreq-hw {
		compatible = "qcom,cpufreq-hw-epss";
		reg = <0x17d91000 0x1000>,
			<0x17d92000 0x1000>,
			<0x17d93000 0x1000>,
			<0x17d09804 0x4>,
			<0x17d09808 0x4>,
			<0x17d0980c 0x4>;
		reg-names = "freq-domain0", "freq-domain1", "freq-domain2",
				"pdmem-domain0", "pdmem-domain1", "pdmem-domain2";
		clocks = <&rpmhcc RPMH_CXO_CLK>, <&gcc GCC_GPLL0>;
		clock-names = "xo", "alternate";
		qcom,lut-row-size = <4>;
		qcom,skip-enable-check;
		qcom,perf-lock-support;
		interrupts = <GIC_SPI 30 IRQ_TYPE_LEVEL_HIGH>,
				<GIC_SPI 31 IRQ_TYPE_LEVEL_HIGH>,
				<GIC_SPI 19 IRQ_TYPE_LEVEL_HIGH>;
		interrupt-names = "dcvsh0_int", "dcvsh1_int", "dcvsh2_int";
		#freq-domain-cells = <2>;
	};

	qcom,cpufreq-hw-debug {
		compatible = "qcom,cpufreq-hw-epss-debug";
		qcom,freq-hw-domain = <&cpufreq_hw 0>, <&cpufreq_hw 1>,
					<&cpufreq_hw 2>;
	};

	apsscc: syscon@17a80000 {
		compatible = "syscon";
		reg = <0x17a80000 0x21000>;
	};

	mccc: syscon@190ba000 {
		compatible = "syscon";
		reg = <0x190ba000 0x54>;
	};

	debugcc: debug-clock-controller@0 {
		compatible = "qcom,diwali-debugcc";
		qcom,gcc = <&gcc>;
		qcom,videocc = <&videocc>;
		qcom,dispcc = <&dispcc>;
		qcom,camcc = <&camcc>;
		qcom,gpucc = <&gpucc>;
		qcom,apsscc = <&apsscc>;
		qcom,mccc = <&mccc>;
		clock-names = "xo_clk_src";
		clocks = <&rpmhcc RPMH_CXO_CLK>;
		#clock-cells = <1>;
	};

	qcom,msm-rtb {
		compatible = "qcom,msm-rtb";
		qcom,rtb-size = <0x100000>;
	};

	cpu_pmu: cpu-pmu {
		compatible = "arm,armv8-pmuv3";
		interrupts = <GIC_PPI 7 IRQ_TYPE_LEVEL_HIGH>;
	};

	vendor_hooks: qcom,cpu-vendor-hooks {
		compatible = "qcom,cpu-vendor-hooks";
	};

	logbuf: qcom,logbuf-vendor-hooks {
		compatible = "qcom,logbuf-vendor-hooks";
	};

	mini_dump_node {
		compatible = "qcom,minidump";
	};

	va_mini_dump {
		compatible = "qcom,va-minidump";
		memory-region = <&va_md_mem>;
		status = "ok";
	};

	qcom,chd {
		compatible = "qcom,core-hang-detect";
		label = "core";
		qcom,threshold-arr = <0x17800058 0x17810058 0x17820058 0x17830058
			0x17840058 0x17850058 0x17860058 0x17870058>;
		qcom,config-arr = <0x17800060 0x17810060 0x17820060 0x17830060
			0x17840060 0x17850060 0x17860060 0x17870060>;
	};

	qcom,mpm2-sleep-counter@c221000 {
		compatible = "qcom,mpm2-sleep-counter";
		reg = <0xc221000 0x1000>;
		clock-frequency = <32768>;
	};

	qcom,sps {
		compatible = "qcom,msm-sps-4k";
		qcom,pipe-attr-ee;
	};

	qcom,msm-imem@146aa000 {
		compatible = "qcom,msm-imem";
		reg = <0x146aa000 0x1000>;
		ranges = <0x0 0x146aa000 0x1000>;
		#address-cells = <1>;
		#size-cells = <1>;

		mem_dump_table@10 {
			compatible = "qcom,msm-imem-mem_dump_table";
			reg = <0x10 0x8>;
		};

		restart_reason@65c {
			compatible = "qcom,msm-imem-restart_reason";
			reg = <0x65c 0x4>;
		};

		dload_type@1c {
			compatible = "qcom,msm-imem-dload-type";
			reg = <0x1c 0x4>;
		};

		boot_stats@6b0 {
			compatible = "qcom,msm-imem-boot_stats";
			reg = <0x6b0 0x20>;
		};

		kaslr_offset@6d0 {
			compatible = "qcom,msm-imem-kaslr_offset";
			reg = <0x6d0 0xc>;
		};

		pil@94c {
			compatible = "qcom,pil-reloc-info";
			reg = <0x94c 0xc8>;
		};

		pil@6dc {
			compatible = "qcom,msm-imem-pil-disable-timeout";
			reg = <0x6dc 0x4>;
		};

		diag_dload@c8 {
			compatible = "qcom,msm-imem-diag-dload";
			reg = <0xc8 0xc8>;
		};
	};

	dload_mode {
		compatible = "qcom,dload-mode";
	};

	cache-controller@19200000 {
		compatible = "qcom,diwali-llcc", "qcom,llcc-v21";
		reg = <0x19200000 0x180000> , <0x19A00000 0x80000>;
		reg-names = "llcc_base", "llcc_broadcast_base";
		interrupts = <GIC_SPI 266 IRQ_TYPE_LEVEL_HIGH>;
		cap-based-alloc-and-pwr-collapse;
		llcc-perfmon {
			compatible = "qcom,llcc-perfmon";
			clocks = <&aoss_qmp QDSS_CLK>;
			clock-names = "qdss_clk";
		};
	};

	qcom,memshare {
		compatible = "qcom,memshare";

		qcom,client_1 {
			compatible = "qcom,memshare-peripheral";
			qcom,peripheral-size = <0x0>;
			qcom,client-id = <0>;
			qcom,allocate-boot-time;
			label = "modem";
		};

		qcom,client_2 {
			compatible = "qcom,memshare-peripheral";
			qcom,peripheral-size = <0x0>;
			qcom,client-id = <2>;
			label = "modem";
		};

		qcom,client_3 {
			compatible = "qcom,memshare-peripheral";
			qcom,peripheral-size = <0x500000>;
			qcom,client-id = <1>;
			qcom,allocate-on-request;
			label = "modem";
		};
	};

	qcom,secure-buffer {
		compatible = "qcom,secure-buffer";
		qcom,vmid-cp-camera-preview-ro;
	};

	tcsr_mutex_block: syscon@1f40000 {
		compatible = "syscon";
		reg = <0x1f40000 0x20000>;
	};

	tcsr_mutex: hwlock {
		compatible = "qcom,tcsr-mutex";
		syscon = <&tcsr_mutex_block 0 0x1000>;
		#hwlock-cells = <1>;
	};

	qcom_tzlog: tz-log@146AA720 {
		compatible = "qcom,tz-log";
		reg = <0x146AA720 0x3000>;
		qcom,hyplog-enabled;
		hyplog-address-offset = <0x410>;
		hyplog-size-offset = <0x414>;
	};

	qcom_qseecom: qseecom@c1700000 {
		compatible = "qcom,qseecom";
		memory-region = <&qseecom_mem>;
		qseecom_mem = <&qseecom_mem>;
		qseecom_ta_mem = <&qseecom_ta_mem>;
		user_contig_mem = <&user_contig_mem>;
		qcom,hlos-num-ce-hw-instances = <1>;
		qcom,hlos-ce-hw-instance = <0>;
		qcom,qsee-ce-hw-instance = <0>;
		qcom,disk-encrypt-pipe-pair = <2>;
		qcom,no-clock-support;
		qcom,appsbl-qseecom-support;
		qcom,commonlib64-loaded-by-uefi;
		qcom,qsee-reentrancy-support = <2>;
	};

	qcom_cedev: qcedev@1de0000 {
		compatible = "qcom,qcedev";
		reg = <0x1de0000 0x20000>,
			<0x1dc4000 0x24000>;
		reg-names = "crypto-base","crypto-bam-base";
		interrupts = <GIC_SPI 272 IRQ_TYPE_LEVEL_HIGH>;
		qcom,bam-pipe-pair = <2>;
		qcom,ce-hw-instance = <0>;
		qcom,ce-device = <0>;
		qcom,ce-hw-shared;
		qcom,bam-ee = <0>;
		qcom,smmu-s1-enable;
		qcom,no-clock-support;
		interconnect-names = "data_path";
		interconnects = <&aggre2_noc MASTER_CRYPTO &mc_virt SLAVE_EBI1>;
		iommus = <&apps_smmu 0x0484 0x0011>;
		qcom,iommu-dma = "atomic";
		dma-coherent;

		qcom_cedev_ns_cb {
			compatible = "qcom,qcedev,context-bank";
			label = "ns_context";
			iommus = <&apps_smmu 0x488 0x0>,
				<&apps_smmu 0x49A 0x0>,
				<&apps_smmu 0x49F 0x0>,
				<&apps_smmu 0x498 0x5>;
			dma-coherent;
		};

		qcom_cedev_s_cb {
			compatible = "qcom,qcedev,context-bank";
			label = "secure_context";
			iommus = <&apps_smmu 0x492 0x0>,
				 <&apps_smmu 0x497 0x0>,
				 <&apps_smmu 0x49B 0x0>,
				 <&apps_smmu 0x49E 0x0>;
			qcom,iommu-vmid = <0x9>;
			qcom,secure-context-bank;
		};
	};

	qcom_rng: qrng@10c3000 {
		compatible = "qcom,msm-rng";
		reg = <0x10c3000 0x1000>;
		qcom,no-qrng-config;
		qcom,no-clock-support;
	};

	smem: qcom,smem {
		compatible = "qcom,smem";
		memory-region = <&smem_mem>;
		hwlocks = <&tcsr_mutex 3>;
	};

	qcom,smp2p-adsp {
		compatible = "qcom,smp2p";
		qcom,smem = <443>, <429>;
		interrupt-parent = <&ipcc_mproc>;
		interrupts = <IPCC_CLIENT_LPASS IPCC_MPROC_SIGNAL_SMP2P
			      IRQ_TYPE_EDGE_RISING>;
		mboxes = <&ipcc_mproc IPCC_CLIENT_LPASS
			  IPCC_MPROC_SIGNAL_SMP2P>;
		qcom,local-pid = <0>;
		qcom,remote-pid = <2>;

		adsp_smp2p_out: master-kernel {
			qcom,entry-name = "master-kernel";
			#qcom,smem-state-cells = <1>;
		};

		adsp_smp2p_in: slave-kernel {
			qcom,entry-name = "slave-kernel";
			interrupt-controller;
			#interrupt-cells = <2>;
		};

		sleepstate_smp2p_out: sleepstate-out {
			qcom,entry-name = "sleepstate";
			#qcom,smem-state-cells = <1>;
		};

		sleepstate_smp2p_in: qcom,sleepstate-in {
			qcom,entry-name = "sleepstate_see";
			interrupt-controller;
			#interrupt-cells = <2>;
		};

		smp2p_rdbg2_out: qcom,smp2p-rdbg2-out {
			qcom,entry-name = "rdbg";
			#qcom,smem-state-cells = <1>;
		};

		smp2p_rdbg2_in: qcom,smp2p-rdbg2-in {
			qcom,entry-name = "rdbg";
			interrupt-controller;
			#interrupt-cells = <2>;
		};
	};

	qcom,smp2p_sleepstate {
		compatible = "qcom,smp2p-sleepstate";
		qcom,smem-states = <&sleepstate_smp2p_out 0>;
		interrupt-parent = <&sleepstate_smp2p_in>;
		interrupts = <0 0>;
		interrupt-names = "smp2p-sleepstate-in";
	};

	qcom,smp2p-cdsp {
		compatible = "qcom,smp2p";
		qcom,smem = <94>, <432>;
		interrupt-parent = <&ipcc_mproc>;
		interrupts = <IPCC_CLIENT_CDSP IPCC_MPROC_SIGNAL_SMP2P
				IRQ_TYPE_EDGE_RISING>;
		mboxes = <&ipcc_mproc IPCC_CLIENT_CDSP IPCC_MPROC_SIGNAL_SMP2P>;
		qcom,local-pid = <0>;
		qcom,remote-pid = <5>;

		cdsp_smp2p_out: master-kernel {
			qcom,entry-name = "master-kernel";
			#qcom,smem-state-cells = <1>;
		};

		cdsp_smp2p_in: slave-kernel {
			qcom,entry-name = "slave-kernel";
			interrupt-controller;
			#interrupt-cells = <2>;
		};

		smp2p_rdbg5_out: qcom,smp2p-rdbg5-out {
			qcom,entry-name = "rdbg";
			#qcom,smem-state-cells = <1>;
		};

		smp2p_rdbg5_in: qcom,smp2p-rdbg5-in {
			qcom,entry-name = "rdbg";
			interrupt-controller;
			#interrupt-cells = <2>;
		};
	};

	qcom,smp2p-modem {
		compatible = "qcom,smp2p";
		qcom,smem = <435>, <428>;
		interrupt-parent = <&ipcc_mproc>;
		interrupts = <IPCC_CLIENT_MPSS IPCC_MPROC_SIGNAL_SMP2P
				IRQ_TYPE_EDGE_RISING>;
		mboxes = <&ipcc_mproc IPCC_CLIENT_MPSS IPCC_MPROC_SIGNAL_SMP2P>;
		qcom,local-pid = <0>;
		qcom,remote-pid = <1>;

		modem_smp2p_out: master-kernel {
			qcom,entry-name = "master-kernel";
			#qcom,smem-state-cells = <1>;
		};

		modem_smp2p_in: slave-kernel {
			qcom,entry-name = "slave-kernel";
			interrupt-controller;
			#interrupt-cells = <2>;
		};

		smp2p_ipa_1_out: qcom,smp2p-ipa-1-out {
			qcom,entry-name = "ipa";
			#qcom,smem-state-cells = <1>;
		};

		/* ipa - inbound entry from mss */
		smp2p_ipa_1_in: qcom,smp2p-ipa-1-in {
			qcom,entry-name = "ipa";
			interrupt-controller;
			#interrupt-cells = <2>;
		};
	};

	qcom,smp2p-wpss {
		compatible = "qcom,smp2p";
		qcom,smem = <617>, <616>;
		interrupt-parent = <&ipcc_mproc>;
		interrupts = <IPCC_CLIENT_WPSS IPCC_MPROC_SIGNAL_SMP2P
			IRQ_TYPE_EDGE_RISING>;
		mboxes = <&ipcc_mproc IPCC_CLIENT_WPSS IPCC_MPROC_SIGNAL_SMP2P>;
		qcom,local-pid = <0>;
		qcom,remote-pid = <13>;

		wpss_smp2p_out: master-kernel {
			qcom,entry-name = "master-kernel";
			#qcom,smem-state-cells = <1>;
		};

		wpss_smp2p_in: slave-kernel {
			qcom,entry-name = "slave-kernel";
			interrupt-controller;
			#interrupt-cells = <2>;
		};

		smp2p_wlan_1_in: qcom,smp2p-wlan-1-in {
			qcom,entry-name = "wlan";
			interrupt-controller;
			#interrupt-cells = <2>;
		};

		smp2p_wlan_1_out: qcom,smp2p-wlan-1-out {
			qcom,entry-name = "wlan";
			#qcom,smem-state-cells = <1>;
		};

		smp2p_wlan_2_in: qcom,smp2p-wlan-2-in {
			qcom,entry-name = "wlan_soc_wake";
			interrupt-controller;
			#interrupt-cells = <2>;
		};

		smp2p_wlan_2_out: qcom,smp2p-wlan-2-out {
			qcom,entry-name = "wlan_soc_wake";
			#qcom,smem-state-cells = <1>;
		};

		smp2p_wlan_3_out: qcom,smp2p-wlan-3-out {
			qcom,entry-name = "wlan_ep_power_save";
			#qcom,smem-state-cells = <1>;
		};
	};

	qcom,glinkpkt {
		compatible = "qcom,glinkpkt";

		qcom,glinkpkt-at-mdm0 {
			qcom,glinkpkt-edge = "mpss";
			qcom,glinkpkt-ch-name = "DS";
			qcom,glinkpkt-dev-name = "at_mdm0";
		};

		qcom,glinkpkt-apr-apps2 {
			qcom,glinkpkt-edge = "adsp";
			qcom,glinkpkt-ch-name = "apr_apps2";
			qcom,glinkpkt-dev-name = "apr_apps2";
		};

		qcom,glinkpkt-data40-cntl {
			qcom,glinkpkt-edge = "mpss";
			qcom,glinkpkt-ch-name = "DATA40_CNTL";
			qcom,glinkpkt-dev-name = "smdcntl8";
		};

		qcom,glinkpkt-data1 {
			qcom,glinkpkt-edge = "mpss";
			qcom,glinkpkt-ch-name = "DATA1";
			qcom,glinkpkt-dev-name = "smd7";
		};

		qcom,glinkpkt-data4 {
			qcom,glinkpkt-edge = "mpss";
			qcom,glinkpkt-ch-name = "DATA4";
			qcom,glinkpkt-dev-name = "smd8";
		};

		qcom,glinkpkt-data11 {
			qcom,glinkpkt-edge = "mpss";
			qcom,glinkpkt-ch-name = "DATA11";
			qcom,glinkpkt-dev-name = "smd11";
		};
	};

	aoss_qmp: power-controller@c300000 {
		compatible = "qcom,diwali-aoss-qmp";
		reg = <0xc300000 0x400>;
		interrupt-parent = <&ipcc_mproc>;
		interrupts = <IPCC_CLIENT_AOP
				IPCC_MPROC_SIGNAL_GLINK_QMP
				IRQ_TYPE_EDGE_RISING>;
		mboxes = <&ipcc_mproc IPCC_CLIENT_AOP
				IPCC_MPROC_SIGNAL_GLINK_QMP>;

		#power-domain-cells = <1>;
		#clock-cells = <0>;
	};

	qmp_aop: qcom,qmp-aop {
		compatible = "qcom,qmp-mbox";
		qcom,qmp = <&aoss_qmp>;
		label = "aop";
		#mbox-cells = <1>;
	};

	qmp_tme: qcom,qmp-tme {
		compatible = "qcom,qmp-mbox";
		qcom,remote-pid = <14>;
		mboxes = <&ipcc_mproc IPCC_CLIENT_TME
				IPCC_MPROC_SIGNAL_GLINK_QMP>;
		mbox-names = "tme_qmp";
		interrupt-parent = <&ipcc_mproc>;
		interrupts = <IPCC_CLIENT_TME
				IPCC_MPROC_SIGNAL_GLINK_QMP
				IRQ_TYPE_EDGE_RISING>;

		label = "tme";
		qcom,early-boot;
		priority = <0>;
		mbox-desc-offset = <0x0>;
		#mbox-cells = <1>;
	};

	qcom,tmecom-qmp-client {
		compatible = "qcom,tmecom-qmp-client";
		mboxes = <&qmp_tme 0>;
		mbox-names = "tmecom";
		label = "tmecom";
		depends-on-supply = <&qmp_tme>;
	};

	adsp_pas: remoteproc-adsp@03000000 {
		compatible = "qcom,diwali-adsp-pas";
		reg = <0x03000000 0x10000>;
		status = "ok";

		clocks = <&rpmhcc RPMH_CXO_CLK>;
		clock-names = "xo";

		cx-supply = <&VDD_LPI_CX_LEVEL>;
		cx-uV-uA = <RPMH_REGULATOR_LEVEL_TURBO 0>;
		mx-supply = <&VDD_LPI_MX_LEVEL>;
		mx-uV-uA = <RPMH_REGULATOR_LEVEL_TURBO 0>;
		reg-names = "cx", "mx";

		interconnects = <&aggre2_noc MASTER_CRYPTO &mc_virt SLAVE_EBI1>;
		interconnect-names = "crypto_ddr";

		qcom,qmp = <&aoss_qmp>;
		memory-region = <&adsp_mem>;

		interrupts-extended = <&pdc 6 IRQ_TYPE_LEVEL_HIGH>,
				      <&adsp_smp2p_in 0 0>,
				      <&adsp_smp2p_in 2 0>,
				      <&adsp_smp2p_in 1 0>,
				      <&adsp_smp2p_in 3 0>;

		interrupt-names = "wdog",
				  "fatal",
				  "handover",
				  "ready",
				  "stop-ack";

		qcom,smem-states = <&adsp_smp2p_out 0>;
		qcom,smem-state-names = "stop";

		glink_edge: glink-edge {
			qcom,remote-pid = <2>;
			transport = "smem";
			mboxes = <&ipcc_mproc IPCC_CLIENT_LPASS
				  IPCC_MPROC_SIGNAL_GLINK_QMP>;
			mbox-names = "adsp_smem";
			interrupt-parent = <&ipcc_mproc>;
			interrupts = <IPCC_CLIENT_LPASS
				      IPCC_MPROC_SIGNAL_GLINK_QMP
				      IRQ_TYPE_EDGE_RISING>;

			label = "adsp";
			qcom,glink-label = "lpass";

			qcom,adsp_qrtr {
				qcom,glink-channels = "IPCRTR";
				qcom,intents = <0x800  5
						0x2000 3
						0x4400 2>;
			};

			qcom,msm_fastrpc_rpmsg {
				compatible = "qcom,msm-fastrpc-rpmsg";
				qcom,glink-channels = "fastrpcglink-apps-dsp";
				qcom,intents = <0x64 64>;
			};
		};
	};

	cdsp_pas: remoteproc-cdsp@32300000 {
		compatible = "qcom,diwali-cdsp-pas";
		reg = <0x32300000 0x10000>;
		status = "ok";

		clocks = <&rpmhcc RPMH_CXO_CLK>;
		clock-names = "xo";

		cx-supply = <&VDD_CX_LEVEL>;
		cx-uV-uA = <RPMH_REGULATOR_LEVEL_TURBO 100000>;
		mx-supply = <&VDD_MXC_LEVEL>;
		mx-uV-uA = <RPMH_REGULATOR_LEVEL_TURBO 100000>;
		reg-names = "cx","mx";

		interconnects = <&nsp_noc MASTER_CDSP_PROC &mc_virt SLAVE_EBI1>,
				<&aggre2_noc MASTER_CRYPTO &mc_virt SLAVE_EBI1>;
		interconnect-names = "rproc_ddr", "crypto_ddr";

		qcom,qmp = <&aoss_qmp>;
		memory-region = <&cdsp_mem>;

		/* Inputs from turing */
		interrupts-extended = <&intc GIC_SPI 578 IRQ_TYPE_LEVEL_HIGH>,
				      <&cdsp_smp2p_in 0 0>,
				      <&cdsp_smp2p_in 2 0>,
				      <&cdsp_smp2p_in 1 0>,
				      <&cdsp_smp2p_in 3 0>;

		interrupt-names = "wdog",
				  "fatal",
				  "handover",
				  "ready",
				  "stop-ack";

		/* Outputs to turing */
		qcom,smem-states = <&cdsp_smp2p_out 0>;
		qcom,smem-state-names = "stop";

		glink-edge {
			qcom,remote-pid = <5>;
			transport = "smem";
			mboxes = <&ipcc_mproc IPCC_CLIENT_CDSP
				  IPCC_MPROC_SIGNAL_GLINK_QMP>;
			mbox-names = "cdsp_smem";
			interrupt-parent = <&ipcc_mproc>;
			interrupts = <IPCC_CLIENT_CDSP
				      IPCC_MPROC_SIGNAL_GLINK_QMP
				      IRQ_TYPE_EDGE_RISING>;

			label = "cdsp";
			qcom,glink-label = "cdsp";

			qcom,cdsp_qrtr {
				qcom,glink-channels = "IPCRTR";
				qcom,intents = <0x800  5
						0x2000 3
						0x4400 2>;
			};

			qcom,msm_fastrpc_rpmsg {
				compatible = "qcom,msm-fastrpc-rpmsg";
				qcom,glink-channels = "fastrpcglink-apps-dsp";
				qcom,intents = <0x64 64>;
			};

			qcom,msm_cdsprm_rpmsg {
				compatible = "qcom,msm-cdsprm-rpmsg";
				qcom,glink-channels = "cdsprmglink-apps-dsp";
				qcom,intents = <0x20 12>;

				msm_cdsp_rm: qcom,msm_cdsp_rm {
					compatible = "qcom,msm-cdsp-rm";
					qcom,qos-cores = <0 1 2 3>;
					qcom,qos-latency-us = <70>;
					qcom,qos-maxhold-ms = <20>;
				};
			};
		};
	};

	modem_pas: remoteproc-mss@04080000 {
		compatible = "qcom,diwali-modem-pas";
		reg = <0x4080000 0x10000>;
		status = "ok";

		clocks = <&rpmhcc RPMH_CXO_CLK>;
		clock-names = "xo";

		cx-supply = <&VDD_CX_LEVEL>;
		cx-uV-uA = <RPMH_REGULATOR_LEVEL_TURBO 100000>;
		mx-supply = <&VDD_MODEM_LEVEL>;
		mx-uV-uA = <RPMH_REGULATOR_LEVEL_TURBO 100000>;
		reg-names = "cx", "mx";

		interconnects = <&mc_virt MASTER_LLCC &mc_virt SLAVE_EBI1>,
				<&aggre2_noc MASTER_CRYPTO &mc_virt SLAVE_EBI1>;
		interconnect-names = "rproc_ddr","crypto_ddr";


		qcom,qmp = <&aoss_qmp>;
		memory-region = <&mpss_mem>;

		/* Inputs from mss */
		interrupts-extended = <&intc GIC_SPI 264 IRQ_TYPE_EDGE_RISING>,
				      <&modem_smp2p_in 0 0>,
				      <&modem_smp2p_in 2 0>,
				      <&modem_smp2p_in 1 0>,
				      <&modem_smp2p_in 3 0>,
				      <&modem_smp2p_in 7 0>;

		interrupt-names = "wdog",
				  "fatal",
				  "handover",
				  "ready",
				  "stop-ack",
				  "shutdown-ack";

		/* Outputs to mss */
		qcom,smem-states = <&modem_smp2p_out 0>;
		qcom,smem-state-names = "stop";

		glink-edge {
			qcom,remote-pid = <1>;
			transport = "smem";
			mboxes = <&ipcc_mproc IPCC_CLIENT_MPSS
				  IPCC_MPROC_SIGNAL_GLINK_QMP>;
			mbox-names = "mpss_smem";
			interrupt-parent = <&ipcc_mproc>;
			interrupts = <IPCC_CLIENT_MPSS
				      IPCC_MPROC_SIGNAL_GLINK_QMP
				      IRQ_TYPE_EDGE_RISING>;

			label = "modem";
			qcom,glink-label = "mpss";

			qcom,modem_qrtr {
				qcom,glink-channels = "IPCRTR";
				qcom,low-latency;
				qcom,intents = <0x800  5
						0x2000 3
						0x4400 2>;
			};

			qcom,modem_ds {
				qcom,glink-channels = "DS";
				qcom,intents = <0x4000 0x2>;
			};
		};
	};

	wpss_pas: remoteproc-wpss@8A00000 {
		compatible = "qcom,diwali-wpss-pas";
		status = "ok";

		memory-region = <&wpss_mem>;

		clocks = <&rpmhcc RPMH_CXO_CLK>;
		clock-names = "xo";

		cx-supply = <&VDD_CX_LEVEL>;
		cx-uV-uA = <RPMH_REGULATOR_LEVEL_TURBO 100000>;
		mx-supply = <&VDD_MXA_LEVEL>;
		mx-uV-uA = <RPMH_REGULATOR_LEVEL_TURBO 100000>;
		reg-names = "cx","mx";

		qcom,qmp = <&aoss_qmp>;

		/* Inputs from wpss */
		interrupts-extended = <&intc GIC_SPI 587 IRQ_TYPE_LEVEL_HIGH>,
				      <&wpss_smp2p_in 0 0>,
				      <&wpss_smp2p_in 2 0>,
				      <&wpss_smp2p_in 1 0>,
				      <&wpss_smp2p_in 3 0>,
				      <&wpss_smp2p_in 7 0>;

		interrupt-names = "wdog",
				   "fatal",
				   "handover",
				   "ready",
				   "stop-ack",
				   "shutdown-ack";

		/* Outputs to wpss */
		qcom,smem-states = <&wpss_smp2p_out 0>;
		qcom,smem-state-names = "stop";

		glink-edge {
			qcom,remote-pid = <13>;
			transport = "smem";
			mboxes = <&ipcc_mproc IPCC_CLIENT_WPSS
				  IPCC_MPROC_SIGNAL_GLINK_QMP>;
			mbox-names = "wpss_smem";
			interrupt-parent = <&ipcc_mproc>;
			interrupts = <IPCC_CLIENT_WPSS
					  IPCC_MPROC_SIGNAL_GLINK_QMP
					  IRQ_TYPE_EDGE_RISING>;

			label = "wpss";
			qcom,glink-label = "wpss";

			qcom,wpss_qrtr {
				qcom,glink-channels = "IPCRTR";
				qcom,intents = <0x800  5
						0x2000 3
						0x4400 2>;
			};

		};
	};

	icnss2: qcom,wcn6750 {
		compatible = "qcom,wcn6750";
		reg = <0x17110040 0x0>,
		      <0xb0000000 0x10000>;
		reg-names = "msi_addr", "smmu_iova_ipa";
		qcom,rproc-handle = <&wpss_pas>;
		iommus = <&apps_smmu 0x1c00 0x1>;
		interrupts = <GIC_SPI 768 IRQ_TYPE_EDGE_RISING>,
			   <GIC_SPI 769 IRQ_TYPE_EDGE_RISING>,
			   <GIC_SPI 770 IRQ_TYPE_EDGE_RISING>,
			   <GIC_SPI 771 IRQ_TYPE_EDGE_RISING>,
			   <GIC_SPI 772 IRQ_TYPE_EDGE_RISING>,
			   <GIC_SPI 773 IRQ_TYPE_EDGE_RISING>,
			   <GIC_SPI 774 IRQ_TYPE_EDGE_RISING>,
			   <GIC_SPI 775 IRQ_TYPE_EDGE_RISING>,
			   <GIC_SPI 776 IRQ_TYPE_EDGE_RISING>,
			   <GIC_SPI 777 IRQ_TYPE_EDGE_RISING>,
			   <GIC_SPI 778 IRQ_TYPE_EDGE_RISING>,
			   <GIC_SPI 779 IRQ_TYPE_EDGE_RISING>,
			   <GIC_SPI 780 IRQ_TYPE_EDGE_RISING>,
			   <GIC_SPI 781 IRQ_TYPE_EDGE_RISING>,
			   <GIC_SPI 782 IRQ_TYPE_EDGE_RISING>,
			   <GIC_SPI 783 IRQ_TYPE_EDGE_RISING>,
			   <GIC_SPI 784 IRQ_TYPE_EDGE_RISING>,
			   <GIC_SPI 785 IRQ_TYPE_EDGE_RISING>,
			   <GIC_SPI 786 IRQ_TYPE_EDGE_RISING>,
			   <GIC_SPI 787 IRQ_TYPE_EDGE_RISING>,
			   <GIC_SPI 788 IRQ_TYPE_EDGE_RISING>,
			   <GIC_SPI 789 IRQ_TYPE_EDGE_RISING>,
			   <GIC_SPI 790 IRQ_TYPE_EDGE_RISING>,
			   <GIC_SPI 791 IRQ_TYPE_EDGE_RISING>,
			   <GIC_SPI 792 IRQ_TYPE_EDGE_RISING>,
			   <GIC_SPI 793 IRQ_TYPE_EDGE_RISING>,
			   <GIC_SPI 794 IRQ_TYPE_EDGE_RISING>,
			   <GIC_SPI 795 IRQ_TYPE_EDGE_RISING>,
			   <GIC_SPI 796 IRQ_TYPE_EDGE_RISING>,
			   <GIC_SPI 797 IRQ_TYPE_EDGE_RISING>,
			   <GIC_SPI 798 IRQ_TYPE_EDGE_RISING>,
			   <GIC_SPI 799 IRQ_TYPE_EDGE_RISING>;

		qcom,iommu-dma = "fastmap";
		qcom,iommu-faults = "stall-disable", "HUPCF", "non-fatal";
		qcom,iommu-dma-addr-pool = <0xa0000000 0x10000000>;
		qcom,iommu-geometry = <0xa0000000 0x10010000>;
		dma-coherent;
		qcom,fw-prefix;
		qcom,wlan;
		qcom,wlan-msa-fixed-region = <&wlan_fw_mem>;
		vdd-cx-mx-supply = <&S7B>;
		qcom,vdd-cx-mx-config = <824000 1120000 0 0 1>;
		vdd-1.8-xo-supply = <&S1B>;
		qcom,vdd-1.8-xo-config = <1872000 2040000 0 0 0>;
		vdd-1.3-rfa-supply = <&S8B>;
		qcom,vdd-1.3-rfa-config = <1256000 1500000 0 0 0>;

		qcom,smem-states = <&smp2p_wlan_1_out 0>,
				   <&smp2p_wlan_2_out 0>,
				   <&smp2p_wlan_3_out 0>;
		qcom,smem-state-names = "wlan-smp2p-out",
					"wlan-soc-wake-smp2p-out",
					"wlan-ep-powersave-smp2p-out";

		icnss_cdev_apss: qcom,icnss_cdev1 {
			#cooling-cells = <2>;
		};

		icnss_cdev_wpss: qcom,icnss_cdev2 {
			#cooling-cells = <2>;
		};

		qcom,smp2p_map_wlan_1_in {
			interrupts-extended = <&smp2p_wlan_1_in 0 0>,
					      <&smp2p_wlan_1_in 1 0>;
			interrupt-names = "qcom,smp2p-force-fatal-error",
					  "qcom,smp2p-early-crash-ind";
		};

		qcom,smp2p_map_wlan_2_in {
			interrupts-extended = <&smp2p_wlan_2_in 0 0>;
			interrupt-names = "qcom,smp2p-soc-wake-ack";
		};
	};

	eud: qcom,msm-eud@88e0000 {
		compatible = "qcom,msm-eud";
		interrupt-names = "eud_irq";
		interrupt-parent = <&pdc>;
		interrupts = <11 IRQ_TYPE_LEVEL_HIGH>;
		reg = <0x088e0000 0x2000>,
			<0x088e2000 0x1000>;
		reg-names = "eud_base", "eud_mode_mgr2";
		clocks = <&gcc GCC_EUSB3_0_CLKREF_EN>;
		clock-names = "eud_clkref_clk";
		qcom,secure-eud-en;
		status = "ok";
	};

	clk_virt: interconnect@0 {
		compatible = "qcom,diwali-clk_virt";
		#interconnect-cells = <1>;
		qcom,bcm-voter-names = "hlos";
		qcom,bcm-voters = <&apps_bcm_voter>;
	};

	mc_virt: interconnect@1 {
		compatible = "qcom,diwali-mc_virt";
		#interconnect-cells = <1>;
		qcom,bcm-voter-names = "hlos", "disp";
		qcom,bcm-voters = <&apps_bcm_voter>, <&disp_bcm_voter>;
	};

	config_noc: interconnect@1500000 {
		reg = <0x1500000 0x1C000>;
		compatible = "qcom,diwali-config_noc";
		#interconnect-cells = <1>;
		qcom,bcm-voter-names = "hlos";
		qcom,bcm-voters = <&apps_bcm_voter>;
	};

	system_noc: interconnect@1680000 {
		reg = <0x1680000 0x1E200>;
		compatible = "qcom,diwali-system_noc";
		#interconnect-cells = <1>;
		qcom,bcm-voter-names = "hlos";
		qcom,bcm-voters = <&apps_bcm_voter>;
	};

	pcie_noc: interconnect@16c0000 {
		reg = <0x16C0000 0xE280>;
		compatible = "qcom,diwali-pcie_anoc";
		#interconnect-cells = <1>;
		qcom,bcm-voter-names = "hlos";
		qcom,bcm-voters = <&apps_bcm_voter>;
	};

	aggre1_noc: interconnect@16e0000 {
		reg = <0x16e0000 0x1C080>;
		compatible = "qcom,diwali-aggre1_noc";
		#interconnect-cells = <1>;
		clocks = <&gcc GCC_AGGRE_UFS_PHY_AXI_CLK>,
			 <&gcc GCC_AGGRE_USB3_PRIM_AXI_CLK>;
		qcom,bcm-voter-names = "hlos";
		qcom,bcm-voters = <&apps_bcm_voter>;
	};

	aggre2_noc: interconnect@1700000 {
		reg = <0x1700000 0x31080>;
		compatible = "qcom,diwali-aggre2_noc";
		#interconnect-cells = <1>;
		clocks = <&gcc GCC_AGGRE_UFS_PHY_AXI_CLK>,
			 <&rpmhcc RPMH_IPA_CLK>;
		qcom,bcm-voter-names = "hlos";
		qcom,bcm-voters = <&apps_bcm_voter>;
	};

	mmss_noc: interconnect@1740000 {
		reg = <0x1740000 0x1f080>;
		compatible = "qcom,diwali-mmss_noc";
		#interconnect-cells = <1>;
		qcom,bcm-voter-names = "hlos", "disp";
		qcom,bcm-voters = <&apps_bcm_voter>, <&disp_bcm_voter>;
	};

	gem_noc: interconnect@19100000 {
		reg = <0x19100000 0xBB800>;
		compatible = "qcom,diwali-gem_noc";
		#interconnect-cells = <1>;
		qcom,bcm-voter-names = "hlos", "disp";
		qcom,bcm-voters = <&apps_bcm_voter>, <&disp_bcm_voter>;
	};

	nsp_noc: interconnect@320C0000 {
		reg = <0x320C0000 0x10000>;
		compatible = "qcom,diwali-nsp_noc";
		#interconnect-cells = <1>;
		qcom,bcm-voter-names = "hlos";
		qcom,bcm-voters = <&apps_bcm_voter>;
	};

	lpass_ag_noc: interconnect@3c40000 {
		reg = <0x3c40000 0x17200>;
		compatible = "qcom,diwali-lpass_ag_noc";
		#interconnect-cells = <1>;
		qcom,bcm-voter-names = "hlos";
		qcom,bcm-voters = <&apps_bcm_voter>;
	};

	qcom,rmtfs_sharedmem@0 {
		compatible = "qcom,sharedmem-uio";
		reg = <0x0 0x280000>;
		reg-names = "rmtfs";
		qcom,client-id = <0x00000001>;
	};

	ufsphy_mem: ufsphy_mem@1d87000 {
		reg = <0x1d87000 0xe10>;
		reg-names = "phy_mem";
		#phy-cells = <0>;

		lanes-per-direction = <2>;
		clock-names = "ref_clk_src",
			"ref_aux_clk", "qref_clk",
			"rx_sym0_mux_clk", "rx_sym1_mux_clk", "tx_sym0_mux_clk",
			"rx_sym0_phy_clk", "rx_sym1_phy_clk", "tx_sym0_phy_clk";
		clocks = <&rpmhcc RPMH_CXO_CLK>,
			<&gcc GCC_UFS_PHY_PHY_AUX_CLK>,
			<&gcc GCC_UFS_0_CLKREF_EN>,
			<&gcc GCC_UFS_PHY_RX_SYMBOL_0_CLK_SRC>,
			<&gcc GCC_UFS_PHY_RX_SYMBOL_1_CLK_SRC>,
			<&gcc GCC_UFS_PHY_TX_SYMBOL_0_CLK_SRC>,
			<&ufs_phy_rx_symbol_0_clk>,
			<&ufs_phy_rx_symbol_1_clk>,
			<&ufs_phy_tx_symbol_0_clk>;
		resets = <&ufshc_mem 0>;
		status = "disabled";
	};

	sdhc2_opp_table: sdhc2-opp-table {
		compatible = "operating-points-v2";

		opp-100000000 {
			opp-hz = /bits/ 64 <100000000>;
			opp-peak-kBps = <1600000 280000>;
			opp-avg-kBps = <50000 0>;
		};

		opp-202000000 {
			opp-hz = /bits/ 64 <202000000>;
			opp-peak-kBps = <8000000 1500000>;
			opp-avg-kBps = <104000 0>;
		};
	};

	sdhc_2: sdhci@8804000 {
		status = "disabled";

		compatible = "qcom,sdhci-msm-v5";
		reg = <0x08804000 0x1000>;
		reg-names = "hc_mem";

		interrupts = <GIC_SPI 207 IRQ_TYPE_LEVEL_HIGH>,
				<GIC_SPI 223 IRQ_TYPE_LEVEL_HIGH>;
		interrupt-names = "hc_irq", "pwr_irq";

		bus-width = <4>;
		no-sdio;
		no-mmc;
		qcom,restore-after-cx-collapse;

		clocks = <&gcc GCC_SDCC2_AHB_CLK>,
			<&gcc GCC_SDCC2_APPS_CLK>;
		clock-names = "iface", "core";

		/* DLL HSR settings. Refer go/hsr - <Target> DLL settings */
		qcom,dll-hsr-list = <0x0007642C 0xA800 0x10
					0x2C010800 0x80040868>;

		iommus = <&apps_smmu 0x540 0x0>;
		dma-coherent;
		qcom,iommu-dma = "fastmap";

		interconnects = <&aggre2_noc MASTER_SDCC_2 &mc_virt SLAVE_EBI1>,
				<&gem_noc MASTER_APPSS_PROC &config_noc
				SLAVE_SDCC_2>;
		interconnect-names = "sdhc-ddr","cpu-sdhc";
		operating-points-v2 = <&sdhc2_opp_table>;

		qos0 {
			mask = <0xf0>;
			vote = <44>;
		};

		qos1 {
			mask = <0x0f>;
			vote = <44>;
		};
	};

	ufshc_mem: ufshc@1d84000 {
		compatible = "qcom,ufshc";
		reg = <0x1d84000 0x3000>,
			<0x1d88000 0x8000>,
			<0x1d90000 0x9000>;
		reg-names = "ufs_mem", "ufs_ice", "ufs_ice_hwkm";
		interrupts = <GIC_SPI 265 IRQ_TYPE_LEVEL_HIGH>;
		phys = <&ufsphy_mem>;
		phy-names = "ufsphy";
		#reset-cells = <1>;

		lanes-per-direction = <2>;
		dev-ref-clk-freq = <0>; /* 19.2 MHz */
		clock-names =
			"core_clk",
			"bus_aggr_clk",
			"iface_clk",
			"core_clk_unipro",
			"core_clk_ice",
			"ref_clk",
			"tx_lane0_sync_clk",
			"rx_lane0_sync_clk",
			"rx_lane1_sync_clk";
		clocks =
			<&gcc GCC_UFS_PHY_AXI_CLK>,
			<&gcc GCC_AGGRE_UFS_PHY_AXI_CLK>,
			<&gcc GCC_UFS_PHY_AHB_CLK>,
			<&gcc GCC_UFS_PHY_UNIPRO_CORE_CLK>,
			<&gcc GCC_UFS_PHY_ICE_CORE_CLK>,
			<&rpmhcc RPMH_CXO_CLK>,
			<&gcc GCC_UFS_PHY_TX_SYMBOL_0_CLK>,
			<&gcc GCC_UFS_PHY_RX_SYMBOL_0_CLK>,
			<&gcc GCC_UFS_PHY_RX_SYMBOL_1_CLK>;
		freq-table-hz =
			<75000000 300000000>,
			<0 0>,
			<0 0>,
			<75000000 300000000>,
			<75000000 300000000>,
			<0 0>,
			<0 0>,
			<0 0>,
			<0 0>;

		interconnects = <&aggre1_noc MASTER_UFS_MEM &mc_virt SLAVE_EBI1>,
		      <&gem_noc MASTER_APPSS_PROC &config_noc SLAVE_UFS_MEM_CFG>;
		interconnect-names = "ufs-ddr", "cpu-ufs";

		qcom,ufs-bus-bw,name = "ufshc_mem";
		qcom,ufs-bus-bw,num-cases = <26>;
		qcom,ufs-bus-bw,num-paths = <2>;
		qcom,ufs-bus-bw,vectors-KBps =
		/*
		 * During HS G3 UFS runs at nominal voltage corner, vote
		 * higher bandwidth to push other buses in the data path
		 * to run at nominal to achieve max throughput.
		 * 4GBps pushes BIMC to run at nominal.
		 * 200MBps pushes CNOC to run at nominal.
		 * Vote for half of this bandwidth for HS G3 1-lane.
		 * For max bandwidth, vote high enough to push the buses
		 * to run in turbo voltage corner.
		 */
		<0 0>, <0 0>,          /* No vote */
		<922 0>, <1000 0>,     /* PWM G1 */
		<1844 0>, <1000 0>,    /* PWM G2 */
		<3688 0>, <1000 0>,    /* PWM G3 */
		<7376 0>, <1000 0>,    /* PWM G4 */
		<1844 0>, <1000 0>,    /* PWM G1 L2 */
		<3688 0>, <1000 0>,    /* PWM G2 L2 */
		<7376 0>, <1000 0>,    /* PWM G3 L2 */
		<14752 0>, <1000 0>,   /* PWM G4 L2 */
		<127796 0>, <1000 0>,  /* HS G1 RA */
		<255591 0>, <1000 0>,  /* HS G2 RA */
		<1492582 0>, <102400 0>,  /* HS G3 RA */
		<2915200 0>, <204800 0>,  /* HS G4 RA */
		<255591 0>, <1000 0>,  /* HS G1 RA L2 */
		<511181 0>, <1000 0>,  /* HS G2 RA L2 */
		<1492582 0>, <204800 0>, /* HS G3 RA L2 */
		<2915200 0>, <409600 0>, /* HS G4 RA L2 */
		<149422 0>, <1000 0>,  /* HS G1 RB */
		<298189 0>, <1000 0>,  /* HS G2 RB */
		<1492582 0>, <102400 0>,  /* HS G3 RB */
		<2915200 0>, <204800 0>,  /* HS G4 RB */
		<298189 0>, <1000 0>,  /* HS G1 RB L2 */
		<596378 0>, <1000 0>,  /* HS G2 RB L2 */
		/* As UFS working in HS G3 RB L2 mode, aggregated
		 * bandwidth (AB) should take care of providing
		 * optimum throughput requested. However, as tested,
		 * in order to scale up CNOC clock, instantaneous
		 * bindwidth (IB) needs to be given a proper value too.
		 */
		<1492582 0>, <204800 409600>, /* HS G3 RB L2 KBPs */
		<2915200 0>, <409600 409600>, /* HS G4 RB L2 */
		<7643136 0>, <307200 0>; /* Max. bandwidth */

		qcom,bus-vector-names = "MIN",
		"PWM_G1_L1", "PWM_G2_L1", "PWM_G3_L1", "PWM_G4_L1",
		"PWM_G1_L2", "PWM_G2_L2", "PWM_G3_L2", "PWM_G4_L2",
		"HS_RA_G1_L1", "HS_RA_G2_L1", "HS_RA_G3_L1", "HS_RA_G4_L1",
		"HS_RA_G1_L2", "HS_RA_G2_L2", "HS_RA_G3_L2", "HS_RA_G4_L2",
		"HS_RB_G1_L1", "HS_RB_G2_L1", "HS_RB_G3_L1", "HS_RB_G4_L1",
		"HS_RB_G1_L2", "HS_RB_G2_L2", "HS_RB_G3_L2", "HS_RB_G4_L2",
		"MAX";

		reset-gpios = <&tlmm 170 GPIO_ACTIVE_LOW>;
		resets = <&gcc GCC_UFS_PHY_BCR>;
		reset-names = "rst";

		iommus = <&apps_smmu 0x20 0x0>;
		qcom,iommu-dma = "fastmap";
		dma-coherent;

		status = "disabled";
		qos0 {
			mask = <0xf0>;
			vote = <44>;
			perf;
		};

		qos1 {
			mask = <0x0f>;
			vote = <44>;
		};
	};

	thermal_zones: thermal-zones {
	};

	qcom,mem-buf-msgq {
		compatible = "qcom,mem-buf-msgq";
	};

	qcom,mem-buf {
		compatible = "qcom,mem-buf";
		qcom,mem-buf-capabilities = "supplier";
		qcom,vmid = <3>;
	};

	qcom,guestvm_loader@e0b00000 {
		compatible = "qcom,guestvm-loader";
		qcom,pas-id = <28>;
		qcom,vmid = <45>;
		qcom,isolate-cpus;
		qcom,reserved-cpus = <0x5>, <0x6>;
		qcom,unisolate-timeout-ms = <12000>;
		qcom,firmware-name = "trustedvm";
		memory-region = <&trust_ui_vm_mem>;
	};

	trust_ui_vm: qcom,trust_ui_vm@e55fc000 {
		reg = <0xe55fc000 0x104000>;
		vm_name = "trustedvm";
		shared-buffers = <&trust_ui_vm_vblk0_ring &trust_ui_vm_swiotlb>;
	};

	qcom,virtio_backend@0 {
		compatible = "qcom,virtio_backend";
		qcom,vm = <&trust_ui_vm>;
		qcom,label = <0x11>;
	};

	qrtr-gunyah {
		compatible = "qcom,qrtr-gunyah";
		qcom,master;
		gunyah-label = <3>;
		peer-name = <2>;
		shared-buffer = <&trust_ui_vm_qrtr>;
	};

	qfprom: qfprom@221c8000 {
		compatible = "qcom,qfprom";
		reg = <0x221c8000 0x1000>;
		#address-cells = <1>;
		#size-cells = <1>;
		read-only;
		ranges;

		adsp_variant: adsp_variant@114 {
			reg = <0x117 0x1>;
			bits = <2 6>;
		};

		feat_conf12: feat_conf12@0130 {
			reg = <0x0130 0x4>;
		};

		feat_conf13: feat_conf13@0134 {
			reg = <0x0134 0x4>;
		};

		gpu_speed_bin: gpu_speed_bin@119 {
			reg = <0x119 0x2>;
			bits = <5 8>;
		};

		gpu_gaming_bin: gpu_gaming_bin@130 {
			reg = <0x130 0x1>;
			bits = <6 1>;
		};
	};

	qfprom_sys: qfprom@0 {
		compatible = "qcom,qfprom-sys";

		nvmem-cells = <&adsp_variant>,
				<&feat_conf12>,
				<&feat_conf13>;
		nvmem-cell-names = "adsp_variant",
				"feat_conf12",
				"feat_conf13";
	};

	qcom,msm-cdsp-loader {
		compatible = "qcom,cdsp-loader";
		qcom,proc-img-to-load = "cdsp";
		qcom,rproc-handle = <&cdsp_pas>;
	};

	qcom,msm-adsprpc-mem {
		compatible = "qcom,msm-adsprpc-mem-region";
		memory-region = <&adsp_mem_heap>;
		restrict-access;
	};

	msm_fastrpc: qcom,msm_fastrpc {
		compatible = "qcom,msm-fastrpc-compute";
		qcom,adsp-remoteheap-vmid = <22 37>;
		qcom,fastrpc-adsp-audio-pdr;
		qcom,fastrpc-adsp-sensors-pdr;
		qcom,rpc-latency-us = <235>;
		qcom,fastrpc-gids = <2908>;
		qcom,qos-cores = <0 1 2 3>;

		qcom,msm_fastrpc_compute_cb1 {
			compatible = "qcom,msm-fastrpc-compute-cb";
			label = "cdsprpc-smd";
			iommus = <&apps_smmu 0x2161 0x0400>,
					 <&apps_smmu 0x1021 0x0420>;
			qcom,iommu-dma-addr-pool = <0x80000000 0x78000000>;
			qcom,iommu-faults = "stall-disable", "HUPCF";
			dma-coherent;
		};

		qcom,msm_fastrpc_compute_cb2 {
			compatible = "qcom,msm-fastrpc-compute-cb";
			label = "cdsprpc-smd";
			iommus = <&apps_smmu 0x2162 0x0400>,
					 <&apps_smmu 0x1022 0x0420>;
			qcom,iommu-dma-addr-pool = <0x80000000 0x78000000>;
			qcom,iommu-faults = "stall-disable", "HUPCF";
			dma-coherent;
		};

		qcom,msm_fastrpc_compute_cb3 {
			compatible = "qcom,msm-fastrpc-compute-cb";
			label = "cdsprpc-smd";
			iommus = <&apps_smmu 0x2163 0x0400>,
					 <&apps_smmu 0x1023 0x0420>;
			qcom,iommu-dma-addr-pool = <0x80000000 0x78000000>;
			qcom,iommu-faults = "stall-disable", "HUPCF";
			dma-coherent;
		};

		qcom,msm_fastrpc_compute_cb4 {
			compatible = "qcom,msm-fastrpc-compute-cb";
			label = "cdsprpc-smd";
			iommus = <&apps_smmu 0x2164 0x0400>,
					 <&apps_smmu 0x1024 0x0420>;
			qcom,iommu-dma-addr-pool = <0x80000000 0x78000000>;
			qcom,iommu-faults = "stall-disable", "HUPCF";
			dma-coherent;
		};

		qcom,msm_fastrpc_compute_cb5 {
			compatible = "qcom,msm-fastrpc-compute-cb";
			label = "cdsprpc-smd";
			iommus = <&apps_smmu 0x2165 0x0400>,
					 <&apps_smmu 0x1025 0x0420>;
			qcom,iommu-dma-addr-pool = <0x80000000 0x78000000>;
			qcom,iommu-faults = "stall-disable", "HUPCF";
			dma-coherent;
		};

		qcom,msm_fastrpc_compute_cb6 {
			compatible = "qcom,msm-fastrpc-compute-cb";
			label = "cdsprpc-smd";
			iommus = <&apps_smmu 0x2166 0x0400>,
					 <&apps_smmu 0x1026 0x0420>;
			qcom,iommu-dma-addr-pool = <0x80000000 0x78000000>;
			qcom,iommu-faults = "stall-disable", "HUPCF";
			dma-coherent;
		};

		qcom,msm_fastrpc_compute_cb7 {
			compatible = "qcom,msm-fastrpc-compute-cb";
			label = "cdsprpc-smd";
			iommus = <&apps_smmu 0x2167 0x0400>,
					 <&apps_smmu 0x1027 0x0420>;
			qcom,iommu-dma-addr-pool = <0x80000000 0x78000000>;
			qcom,iommu-faults = "stall-disable", "HUPCF";
			dma-coherent;
		};

		qcom,msm_fastrpc_compute_cb8 {
			compatible = "qcom,msm-fastrpc-compute-cb";
			label = "cdsprpc-smd";
			iommus = <&apps_smmu 0x2168 0x0400>,
					 <&apps_smmu 0x1028 0x0420>;
			qcom,iommu-dma-addr-pool = <0x80000000 0x78000000>;
			qcom,iommu-faults = "stall-disable", "HUPCF";
			dma-coherent;
		};

		qcom,msm_fastrpc_compute_cb9 {
			compatible = "qcom,msm-fastrpc-compute-cb";
			label = "cdsprpc-smd";
			qcom,secure-context-bank;
			iommus = <&apps_smmu 0x2169 0x0400>,
					 <&apps_smmu 0x1029 0x0420>;
			qcom,iommu-dma-addr-pool = <0x60000000 0x78000000>;
			qcom,iommu-faults = "stall-disable", "HUPCF";
			qcom,iommu-vmid = <0xA>;	/* VMID_CP_PIXEL */
			dma-coherent;
		};

		qcom,msm_fastrpc_compute_cb10 {
			compatible = "qcom,msm-fastrpc-compute-cb";
			label = "adsprpc-smd";
			iommus = <&apps_smmu 0x1803 0x0>;
			qcom,iommu-dma-addr-pool = <0x80000000 0x78000000>;
			qcom,iommu-faults = "stall-disable", "HUPCF";
			dma-coherent;
		};

		qcom,msm_fastrpc_compute_cb11 {
			compatible = "qcom,msm-fastrpc-compute-cb";
			label = "adsprpc-smd";
			iommus = <&apps_smmu 0x1804 0x0>;
			qcom,iommu-dma-addr-pool = <0x80000000 0x78000000>;
			qcom,iommu-faults = "stall-disable", "HUPCF";
			dma-coherent;
		};

		qcom,msm_fastrpc_compute_cb12 {
			compatible = "qcom,msm-fastrpc-compute-cb";
			label = "adsprpc-smd";
			iommus = <&apps_smmu 0x1805 0x0>;
			qcom,iommu-dma-addr-pool = <0x80000000 0x78000000>;
			qcom,iommu-faults = "stall-disable", "HUPCF";
			dma-coherent;
			shared-cb = <5>;
		};

		qcom,msm_fastrpc_compute_cb13 {
			compatible = "qcom,msm-fastrpc-compute-cb";
			label = "cdsprpc-smd";
			iommus = <&apps_smmu 0x102B 0x0420>,
					 <&apps_smmu 0x216B 0x0400>;
			qcom,iommu-dma-addr-pool = <0x80000000 0x78000000>;
			qcom,iommu-faults = "stall-disable", "HUPCF";
			dma-coherent;
		};

		qcom,msm_fastrpc_compute_cb14 {
			compatible = "qcom,msm-fastrpc-compute-cb";
			label = "cdsprpc-smd";
			iommus = <&apps_smmu 0x102C 0x0420>,
					 <&apps_smmu 0x216C 0x0400>;
			qcom,iommu-dma-addr-pool = <0x80000000 0x78000000>;
			qcom,iommu-faults = "stall-disable", "HUPCF";
			dma-coherent;
		};

		qcom,msm_fastrpc_compute_cb15 {
			compatible = "qcom,msm-fastrpc-compute-cb";
			label = "cdsprpc-smd";
			iommus = <&apps_smmu 0x102D 0x0420>,
					 <&apps_smmu 0x216D 0x0400>;
			qcom,iommu-dma-addr-pool = <0x80000000 0x78000000>;
			qcom,iommu-faults = "stall-disable", "HUPCF";
			dma-coherent;
		};

		qcom,msm_fastrpc_compute_cb16 {
			compatible = "qcom,msm-fastrpc-compute-cb";
			label = "cdsprpc-smd";
			iommus = <&apps_smmu 0x102E 0x0420>,
					 <&apps_smmu 0x216E 0x0400>;
			qcom,iommu-dma-addr-pool = <0x80000000 0x78000000>;
			qcom,iommu-faults = "stall-disable", "HUPCF";
			dma-coherent;
		};
	};

	mhi_qrtr_cnss {
		compatible = "qcom,qrtr-mhi";
		qcom,dev-id = <0x1103>;
		qcom,net-id = <0>;
		qcom,low-latency;
	};

	spmi_bus: spmi0_bus: qcom,spmi@c42d000 {
		compatible = "qcom,spmi-pmic-arb";
		reg = <0xc42d000 0x4000>,
		      <0xc400000 0x3000>,
		      <0xc500000 0x400000>,
		      <0xc440000 0x80000>,
		      <0xc4c0000 0x10000>;
		reg-names = "cnfg", "core", "chnls", "obsrvr", "intr";
		interrupts-extended = <&pdc 1 IRQ_TYPE_LEVEL_HIGH>;
		interrupt-names = "periph_irq";
		interrupt-controller;
		#interrupt-cells = <4>;
		#address-cells = <2>;
		#size-cells = <0>;
		cell-index = <0>;
		qcom,channel = <0>;
		qcom,ee = <0>;
		qcom,bus-id = <0>;
	};

	spmi1_bus: qcom,spmi@c432000 {
		compatible = "qcom,spmi-pmic-arb";
		reg = <0xc432000 0x4000>,
		      <0xc400000 0x3000>,
		      <0xc500000 0x400000>,
		      <0xc440000 0x80000>,
		      <0xc4d0000 0x10000>;
		reg-names = "cnfg", "core", "chnls", "obsrvr", "intr";
		interrupts-extended = <&pdc 3 IRQ_TYPE_LEVEL_HIGH>;
		interrupt-names = "periph_irq";
		interrupt-controller;
		#interrupt-cells = <4>;
		#address-cells = <2>;
		#size-cells = <0>;
		cell-index = <0>;
		qcom,channel = <0>;
		qcom,ee = <0>;
		qcom,bus-id = <1>;
		depends-on-supply = <&spmi0_bus>;
	};

	spmi0_debug_bus: qcom,spmi-debug@10b14000 {
		compatible = "qcom,spmi-pmic-arb-debug";
		reg = <0x10b14000 0x60>, <0x221c8784 0x4>;
		reg-names = "core", "fuse";
		clocks = <&aoss_qmp>;
		clock-names = "core_clk";
		qcom,fuse-enable-bit = <18>;
		#address-cells = <2>;
		#size-cells = <0>;
		depends-on-supply = <&spmi1_bus>;

		qcom,pmk8350-debug@0 {
			compatible = "qcom,spmi-pmic";
			reg = <0 SPMI_USID>;
			#address-cells = <2>;
			#size-cells = <0>;
			qcom,can-sleep;
		};

		qcom,pm7325-debug@1 {
			compatible = "qcom,spmi-pmic";
			reg = <1 SPMI_USID>;
			#address-cells = <2>;
			#size-cells = <0>;
			qcom,can-sleep;
		};

		qcom,pm8350c-debug@2 {
			compatible = "qcom,spmi-pmic";
			reg = <2 SPMI_USID>;
			#address-cells = <2>;
			#size-cells = <0>;
			qcom,can-sleep;
		};

		qcom,pmr735a-debug@4 {
			compatible = "qcom,spmi-pmic";
			reg = <4 SPMI_USID>;
			#address-cells = <2>;
			#size-cells = <0>;
			qcom,can-sleep;
		};

		qcom,pmg1110-debug@a {
			compatible = "qcom,spmi-pmic";
			reg = <10 SPMI_USID>;
			#address-cells = <2>;
			#size-cells = <0>;
			qcom,can-sleep;
		};
	};

	qcom,pmic_glink {
		compatible = "qcom,pmic-glink";
		qcom,pmic-glink-channel = "PMIC_RTR_ADSP_APPS";
		qcom,subsys-name = "lpass";
		qcom,protection-domain = "tms/servreg", "msm/adsp/charger_pd";
		depends-on-supply = <&ipcc_mproc>;
		status = "disabled";

		battery_charger: qcom,battery_charger {
			compatible = "qcom,battery-charger";
			status = "disabled";
		};

		ucsi: qcom,ucsi {
			compatible = "qcom,ucsi-glink";
			status = "disabled";
		};

		altmode: qcom,altmode {
			compatible = "qcom,altmode-glink";
			#altmode-cells = <1>;
			status = "disabled";
		};
	};

	qcom,msm_gsi {
		compatible = "qcom,msm_gsi";
	};

	qcom,rmnet-ipa {
		compatible = "qcom,rmnet-ipa3";
		qcom,rmnet-ipa-ssr;
		qcom,ipa-platform-type-msm;
		qcom,ipa-advertise-sg-support;
		qcom,ipa-napi-enable;
	};

	qcom,ipa_fws {
		compatible = "qcom,pil-tz-generic";
		qcom,pas-id = <0xf>;
		qcom,firmware-name = "ipa_fws";
		qcom,pil-force-shutdown;
		status = "disabled";
	};

	ipa_hw: qcom,ipa@3e00000 {
		compatible = "qcom,ipa";
		reg =
			<0x3e00000 0x84000>,
			<0x3e04000 0xfc000>;
		reg-names = "ipa-base", "gsi-base";
		pas-ids = <0xf>;
		firmware-names = "ipa_fws";
		memory-regions = <&ipa_gsi_mem>;
		qcom,ipa-cfg-offset = <0x0140000>;
		interrupts =
			<0 654 IRQ_TYPE_LEVEL_HIGH>,
			<0 432 IRQ_TYPE_LEVEL_HIGH>;
		interrupt-names = "ipa-irq", "gsi-irq";
		qcom,ipa-hw-ver = <22>; /* IPA core version = IPAv5.1 */
		qcom,ipa-hw-mode = <0>;
		qcom,platform-type = <1>; /* MSM platform */
		qcom,ee = <0>;
		qcom,entire-ipa-block-size = <0x200000>;
		qcom,use-ipa-tethering-bridge;
		qcom,modem-cfg-emb-pipe-flt;
		qcom,ipa-wdi3-over-gsi;
		qcom,arm-smmu;
		qcom,smmu-fast-map;
		qcom,use-64-bit-dma-mask;
		qcom,ipa-endp-delay-wa-v2;
		qcom,ipa-ulso-wa;
		qcom,lan-rx-napi;
		qcom,tx-napi;
		qcom,tx-poll;
		qcom,wan-use-skb-page;
		qcom,rmnet-ctl-enable;
		qcom,rmnet-ll-enable;
		qcom,ipa-uc-holb-monitor;
		qcom,ipa-holb-monitor-poll-period = <5>;
		qcom,ipa-holb-monitor-max-cnt-wlan = <10>;
		qcom,ipa-holb-monitor-max-cnt-usb = <10>;
		qcom,ipa-holb-monitor-max-cnt-11ad = <10>;
		qcom,register-collection-on-crash;
		qcom,testbus-collection-on-crash;
		qcom,non-tn-collection-on-crash;
		qcom,tx-wrapper-cache-max-size = <400>;
		qcom,ipa-gpi-event-rp-ddr;
		qcom,ulso-supported;
		qcom,ulso-ip-id-min-linux-val = <0>;
		qcom,ulso-ip-id-max-linux-val = <0xffff>;
		qcom,ulso-ip-id-min-windows-val = <0>;
		qcom,ulso-ip-id-max-windows-val = <0x7fff>;
		qcom,max_num_smmu_cb = <4>;
		clock-names = "core_clk";
		clocks = <&rpmhcc RPMH_IPA_CLK>;
		qcom,interconnect,num-cases = <5>;
		qcom,interconnect,num-paths = <3>;
		interconnects = <&aggre2_noc MASTER_IPA &gem_noc SLAVE_LLCC>,
			<&mc_virt MASTER_LLCC &mc_virt SLAVE_EBI1>,
			<&gem_noc MASTER_APPSS_PROC &config_noc SLAVE_IPA_CFG>;
		interconnect-names = "ipa_to_llcc", "llcc_to_ebi1", "appss_to_ipa";
		/* No vote */
		qcom,no-vote =
		<0 0 0 0 0 0>;

		/* SVS2 */
		qcom,svs2 =
		<590000 0 590000 1900000 0 76800>;

		/* SVS */
		qcom,svs =
		<1200000 0 1200000 2800000 0 150000>;

		/* NOMINAL */
		qcom,nominal =
		<2400000 0 2400000 5500000 0 400000>;

		/* TURBO */
		qcom,turbo =
		<3600000 0 3600000 5500000 0 400000>;

		qcom,bus-vector-names = "MIN", "SVS2", "SVS", "NOMINAL",
			"TURBO";
		qcom,throughput-threshold = <2000 4000 8000>;
		qcom,scaling-exceptions = <>;

		/* smp2p information */
		qcom,smp2p_map_ipa_1_out {
			compatible = "qcom,smp2p-map-ipa-1-out";
			qcom,smem-states = <&smp2p_ipa_1_out 0>;
			qcom,smem-state-names = "ipa-smp2p-out";
		};

		qcom,smp2p_map_ipa_1_in {
			compatible = "qcom,smp2p-map-ipa-1-in";
			interrupts-extended = <&smp2p_ipa_1_in 0 0>;
			interrupt-names = "ipa-smp2p-in";
		};

		ipa_smmu_ap: ipa_smmu_ap {
			compatible = "qcom,ipa-smmu-ap-cb";
			iommus = <&apps_smmu 0x4a0 0x0>;
			qcom,iommu-dma-addr-pool = <0x20000000 0x20000000>;
			qcom,additional-mapping =
				/* modem tables in IMEM */
				<0x146A8000 0x146A8000 0x2000>;
			qcom,iommu-dma = "atomic";
			qcom,ipa-q6-smem-size = <36864>;
		};

		ipa_smmu_wlan: ipa_smmu_wlan {
			compatible = "qcom,ipa-smmu-wlan-cb";
			iommus = <&apps_smmu 0x4a1 0x0>;
			qcom,iommu-dma = "atomic";
		};

		ipa_smmu_uc: ipa_smmu_uc {
			compatible = "qcom,ipa-smmu-uc-cb";
			iommus = <&apps_smmu 0x4a2 0x0>;
			qcom,iommu-dma-addr-pool = <0x20000000 0x20000000>;
			qcom,iommu-dma = "atomic";
		};

		ipa_smmu_11ad: ipa_smmu_11ad {
			compatible = "qcom,ipa-smmu-11ad-cb";
			iommus = <&apps_smmu 0x4a3 0x0>;
			dma-coherent;
			qcom,shared-cb;
			qcom,iommu-group = <>;
		};
	};

	hyp_core_ctl: qcom,hyp-core-ctl {
		compatible = "qcom,hyp-core-ctl";
		status = "ok";
	};
};

#include "diwali-qupv3.dtsi"
#include "diwali-debug.dtsi"
#include "diwali-coresight.dtsi"
#include "diwali-pinctrl.dtsi"
#include "diwali-dma-heaps.dtsi"
#include "diwali-gdsc.dtsi"
#include "ipcc-test-diwali.dtsi"
#include "msm-arm-smmu-diwali.dtsi"
#include "diwali-pcie.dtsi"

&qupv3_se5_2uart {
	status = "ok";
};

&qupv3_se2_i2c {
	status = "ok";
	nq@64 {
		compatible = "rtc6226";
		reg = <0x64>;
		fmint-gpio = <&tlmm 125 0>;
		vdd-supply = <&L11C>;
		rtc6226,vdd-supply-voltage = <2800000 2800000>;
		rtc6226,vdd-load = <15000>;
		vio-supply = <&L18B>;
		rtc6226,vio-supply-voltage = <1800000 1800000>;
	};

	fsa4480: fsa4480@42 {
		compatible = "qcom,fsa4480-i2c";
		reg = <0x42>;
	};
};

&cam_cc_bps_gdsc {
	clocks = <&gcc GCC_CAMERA_AHB_CLK>;
	clock-names = "ahb_clk";
	parent-supply = <&VDD_CAM_CX_LEVEL>;
	status = "ok";
};

&cam_cc_ife_0_gdsc {
	clocks = <&gcc GCC_CAMERA_AHB_CLK>;
	clock-names = "ahb_clk";
	parent-supply = <&VDD_CAM_CX_LEVEL>;
	status = "ok";
};

&cam_cc_ife_1_gdsc {
	clocks = <&gcc GCC_CAMERA_AHB_CLK>;
	clock-names = "ahb_clk";
	parent-supply = <&VDD_CAM_CX_LEVEL>;
	status = "ok";
};

&cam_cc_ife_2_gdsc {
	clocks = <&gcc GCC_CAMERA_AHB_CLK>;
	clock-names = "ahb_clk";
	parent-supply = <&VDD_CAM_CX_LEVEL>;
	status = "ok";
};

&cam_cc_ipe_0_gdsc {
	clocks = <&gcc GCC_CAMERA_AHB_CLK>;
	clock-names = "ahb_clk";
	parent-supply = <&VDD_CAM_CX_LEVEL>;
	status = "ok";
};

&cam_cc_titan_top_gdsc {
	clocks = <&gcc GCC_CAMERA_AHB_CLK>;
	clock-names = "ahb_clk";
	parent-supply = <&VDD_CAM_CX_LEVEL>;
	status = "ok";
};

&disp_cc_mdss_core_gdsc {
	clocks = <&gcc GCC_DISP_AHB_CLK>;
	clock-names = "ahb_clk";
	parent-supply = <&VDD_CX_LEVEL>;
	status = "ok";
};

&disp_cc_mdss_core_int2_gdsc {
	clocks = <&gcc GCC_DISP_AHB_CLK>;
	clock-names = "ahb_clk";
	parent-supply = <&VDD_CX_LEVEL>;
	status = "ok";
};

&gcc_ufs_phy_gdsc {
	parent-supply = <&VDD_CX_LEVEL>;
	status = "ok";
};

&gcc_usb30_prim_gdsc {
	parent-supply = <&VDD_CX_LEVEL>;
	status = "ok";
};

&hlos1_vote_mmnoc_mmu_tbu_hf0_gdsc {
	parent-supply = <&VDD_CX_LEVEL>;
	status = "ok";
};

&hlos1_vote_mmnoc_mmu_tbu_hf1_gdsc {
	parent-supply = <&VDD_CX_LEVEL>;
	status = "ok";
};

&hlos1_vote_mmnoc_mmu_tbu_hf2_gdsc {
	parent-supply = <&VDD_CX_LEVEL>;
	status = "ok";
};

&hlos1_vote_mmnoc_mmu_tbu_hf3_gdsc {
	parent-supply = <&VDD_CX_LEVEL>;
	status = "ok";
};

&hlos1_vote_mmnoc_mmu_tbu_sf0_gdsc {
	parent-supply = <&VDD_CX_LEVEL>;
	status = "ok";
};

&hlos1_vote_mmnoc_mmu_tbu_sf1_gdsc {
	parent-supply = <&VDD_CX_LEVEL>;
	status = "ok";
};

&hlos1_vote_turing_mmu_tbu0_gdsc {
	parent-supply = <&VDD_CX_LEVEL>;
	status = "ok";
};

&hlos1_vote_turing_mmu_tbu1_gdsc {
	parent-supply = <&VDD_CX_LEVEL>;
	status = "ok";
};

&gpu_cc_cx_gdsc {
	clocks = <&gcc GCC_GPU_CFG_AHB_CLK>;
	clock-names = "ahb_clk";
	parent-supply = <&VDD_CX_LEVEL>;
	status = "ok";
};

&gpu_cc_gx_gdsc {
	clocks = <&gcc GCC_GPU_CFG_AHB_CLK>;
	clock-names = "ahb_clk";
	parent-supply = <&VDD_GFX_LEVEL>;
	qcom,skip-disable-before-sw-enable;
	status = "ok";
};

&video_cc_mvs0_gdsc {
	clocks = <&gcc GCC_VIDEO_AHB_CLK>;
	clock-names = "ahb_clk";
	parent-supply = <&VDD_MXC_LEVEL>;
	status = "ok";
};

&video_cc_mvs0c_gdsc {
	clocks = <&gcc GCC_VIDEO_AHB_CLK>;
	clock-names = "ahb_clk";
	parent-supply = <&VDD_MXC_LEVEL>;
	status = "ok";
};

&video_cc_mvs1_gdsc {
	clocks = <&gcc GCC_VIDEO_AHB_CLK>;
	clock-names = "ahb_clk";
	parent-supply = <&VDD_MXC_LEVEL>;
	status = "ok";
};

&video_cc_mvs1c_gdsc {
	clocks = <&gcc GCC_VIDEO_AHB_CLK>;
	clock-names = "ahb_clk";
	parent-supply = <&VDD_MXC_LEVEL>;
	status = "ok";
};

&qupv3_se7_4uart {
	status = "ok";
};

#include "diwali-regulators.dtsi"
#include "diwali-usb.dtsi"
#include "diwali-gpu.dtsi"
#include "diwali-thermal.dtsi"
#include "msm-rdbg.dtsi"

